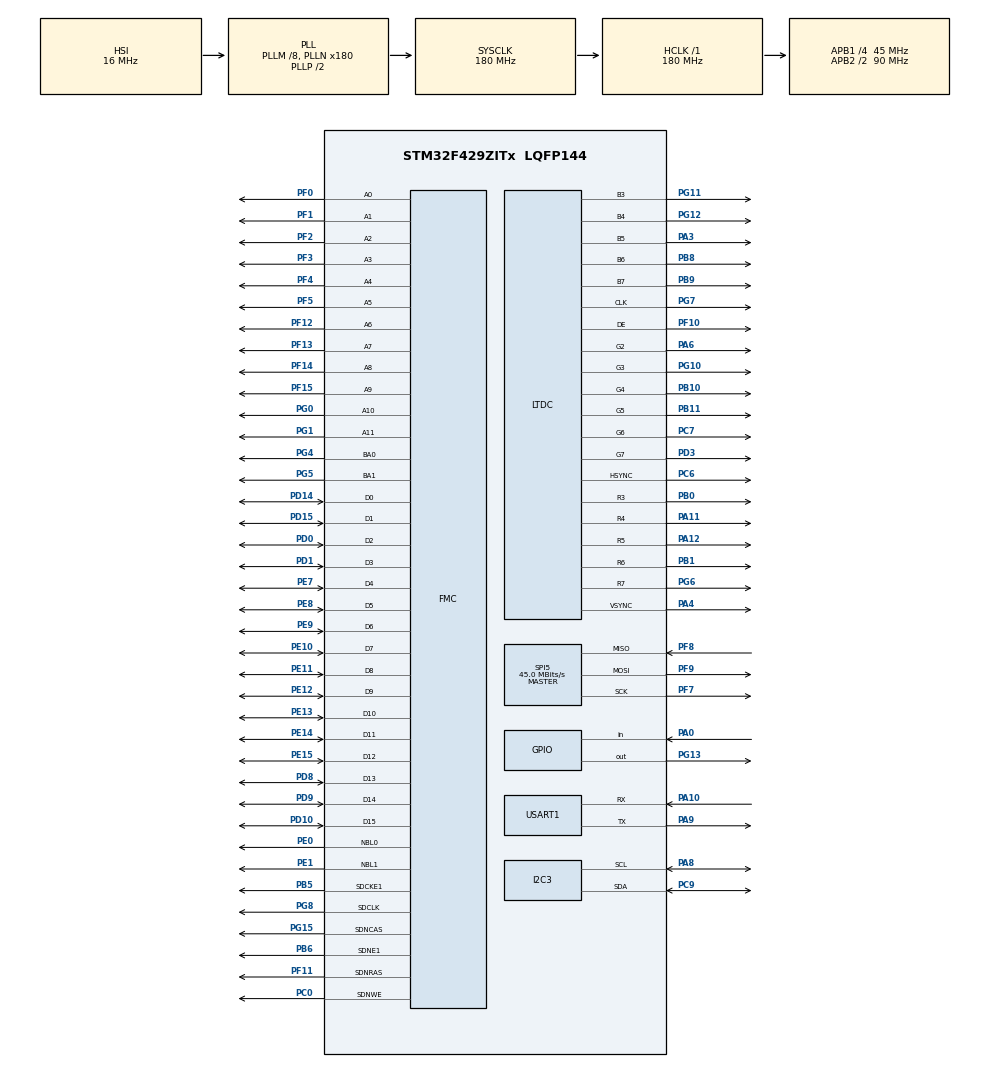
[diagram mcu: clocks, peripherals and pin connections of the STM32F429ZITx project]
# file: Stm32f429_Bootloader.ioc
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Mcu.Family=STM32F4
Mcu.Name=STM32F429ZITx
Mcu.Package=LQFP144
NVIC.PriorityGroup=NVIC_PRIORITYGROUP_4
PA0/WKUP.Signal=GPIO_Input
PA10.Mode=Asynchronous
PA10.Signal=USART1_RX
PA11.Mode=RGB565
PA11.Signal=LTDC_R4
PA12.Mode=RGB565
PA12.Signal=LTDC_R5
PA3.Mode=RGB565
PA3.Signal=LTDC_B5
PA4.Mode=RGB565
PA4.Signal=LTDC_VSYNC
PA6.Mode=RGB565
PA6.Signal=LTDC_G2
PA8.Mode=I2C
PA8.Signal=I2C3_SCL
PA9.Mode=Asynchronous
PA9.Signal=USART1_TX
PB0.Mode=RGB565
PB0.Signal=LTDC_R3
PB1.Mode=RGB565
PB1.Signal=LTDC_R6
PB10.Mode=RGB565
PB10.Signal=LTDC_G4
PB11.Mode=RGB565
PB11.Signal=LTDC_G5
PB5.Mode=SdramChipSelect2_1
PB5.Signal=FMC_SDCKE1
PB6.Mode=SdramChipSelect2_1
PB6.Signal=FMC_SDNE1
PB8.Mode=RGB565
PB8.Signal=LTDC_B6
PB9.Mode=RGB565
PB9.Signal=LTDC_B7
PC0.Signal=FMC_SDNWE
PC6.Mode=RGB565
PC6.Signal=LTDC_HSYNC
PC7.Mode=RGB565
PC7.Signal=LTDC_G6
PC9.Mode=I2C
PC9.Signal=I2C3_SDA
PD0.Signal=FMC_D2_DA2
PD1.Signal=FMC_D3_DA3
PD10.Signal=FMC_D15_DA15
PD14.Signal=FMC_D0_DA0
PD15.Signal=FMC_D1_DA1
PD3.Mode=RGB565
PD3.Signal=LTDC_G7
PD8.Signal=FMC_D13_DA13
PD9.Signal=FMC_D14_DA14
PE0.Signal=FMC_NBL0
PE1.Signal=FMC_NBL1
PE10.Signal=FMC_D7_DA7
PE11.Signal=FMC_D8_DA8
PE12.Signal=FMC_D9_DA9
PE13.Signal=FMC_D10_DA10
PE14.Signal=FMC_D11_DA11
PE15.Signal=FMC_D12_DA12
PE7.Signal=FMC_D4_DA4
PE8.Signal=FMC_D5_DA5
PE9.Signal=FMC_D6_DA6
PF0.Signal=FMC_A0
PF1.Signal=FMC_A1
PF10.Mode=RGB565
PF10.Signal=LTDC_DE
PF11.Signal=FMC_SDNRAS
PF12.Signal=FMC_A6
PF13.Signal=FMC_A7
PF14.Signal=FMC_A8
PF15.Signal=FMC_A9
PF2.Signal=FMC_A2
PF3.Signal=FMC_A3
PF4.Signal=FMC_A4
PF5.Signal=FMC_A5
PF7.Mode=Full_Duplex_Master
PF7.Signal=SPI5_SCK
PF8.Mode=Full_Duplex_Master
PF8.Signal=SPI5_MISO
PF9.Mode=Full_Duplex_Master
PF9.Signal=SPI5_MOSI
PG0.Signal=FMC_A10
PG1.Signal=FMC_A11
PG10.Mode=RGB565
PG10.Signal=LTDC_G3
PG11.Mode=RGB565
PG11.Signal=LTDC_B3
PG12.Mode=RGB565
PG12.Signal=LTDC_B4
PG13.Signal=GPIO_Output
PG15.Signal=FMC_SDNCAS
PG4.Signal=FMC_A14_BA0
PG5.Signal=FMC_A15_BA1
PG6.Mode=RGB565
PG6.Signal=LTDC_R7
PG7.Mode=RGB565
PG7.Signal=LTDC_CLK
PG8.Signal=FMC_SDCLK
ProjectManager.HeapSize=0x200
ProjectManager.StackSize=0x400
ProjectManager.TargetToolchain=STM32CubeIDE
RCC.48MHZClocksFreq_Value=120000000
RCC.AHBFreq_Value=180000000
RCC.APB1CLKDivider=RCC_HCLK_DIV4
RCC.APB1Freq_Value=45000000
RCC.APB1TimFreq_Value=90000000
RCC.APB2CLKDivider=RCC_HCLK_DIV2
RCC.APB2Freq_Value=90000000
RCC.APB2TimFreq_Value=180000000
RCC.CortexFreq_Value=180000000
RCC.HCLKFreq_Value=180000000
RCC.HSE_VALUE=8000000
RCC.HSI_VALUE=16000000
RCC.LSE_VALUE=32768
RCC.PLLM=8
RCC.PLLN=180
RCC.PLLQ=3
RCC.PLLSAIDivR=RCC_PLLSAIDIVR_16
RCC.PLLSAIN=192
RCC.PLLSAIR=4
RCC.SYSCLKFreq_VALUE=180000000
RCC.SYSCLKSource=RCC_SYSCLKSOURCE_PLLCLK
RCC.VCOOutputFreq_Value=360000000
SH.FMC_A0.0=FMC_A0,12b-sda1
SH.FMC_A1.0=FMC_A1,12b-sda1
SH.FMC_A10.0=FMC_A10,12b-sda1
SH.FMC_A11.0=FMC_A11,12b-sda1
SH.FMC_A14_BA0.0=FMC_BA0,FourSdramBanks1
SH.FMC_A15_BA1.0=FMC_BA1,FourSdramBanks1
SH.FMC_A2.0=FMC_A2,12b-sda1
SH.FMC_A3.0=FMC_A3,12b-sda1
SH.FMC_A4.0=FMC_A4,12b-sda1
SH.FMC_A5.0=FMC_A5,12b-sda1
SH.FMC_A6.0=FMC_A6,12b-sda1
SH.FMC_A7.0=FMC_A7,12b-sda1
SH.FMC_A8.0=FMC_A8,12b-sda1
SH.FMC_A9.0=FMC_A9,12b-sda1
SH.FMC_D0_DA0.0=FMC_D0,sd-16b-d1
SH.FMC_D10_DA10.0=FMC_D10,sd-16b-d1
SH.FMC_D11_DA11.0=FMC_D11,sd-16b-d1
SH.FMC_D12_DA12.0=FMC_D12,sd-16b-d1
SH.FMC_D13_DA13.0=FMC_D13,sd-16b-d1
SH.FMC_D14_DA14.0=FMC_D14,sd-16b-d1
SH.FMC_D15_DA15.0=FMC_D15,sd-16b-d1
SH.FMC_D1_DA1.0=FMC_D1,sd-16b-d1
SH.FMC_D2_DA2.0=FMC_D2,sd-16b-d1
SH.FMC_D3_DA3.0=FMC_D3,sd-16b-d1
SH.FMC_D4_DA4.0=FMC_D4,sd-16b-d1
SH.FMC_D5_DA5.0=FMC_D5,sd-16b-d1
SH.FMC_D6_DA6.0=FMC_D6,sd-16b-d1
SH.FMC_D7_DA7.0=FMC_D7,sd-16b-d1
SH.FMC_D8_DA8.0=FMC_D8,sd-16b-d1
SH.FMC_D9_DA9.0=FMC_D9,sd-16b-d1
SH.FMC_NBL0.0=FMC_NBL0,Sd2ByteEnable1
SH.FMC_NBL1.0=FMC_NBL1,Sd2ByteEnable1
SH.FMC_SDCLK.0=FMC_SDCLK,12b-sda1
SH.FMC_SDNCAS.0=FMC_SDNCAS,12b-sda1
SH.FMC_SDNRAS.0=FMC_SDNRAS,12b-sda1
SH.FMC_SDNWE.0=FMC_SDNWE,12b-sda1
SPI5.CalculateBaudRate=45.0 MBits/s
SPI5.Direction=SPI_DIRECTION_2LINES
SPI5.Mode=SPI_MODE_MASTER
SPI5.VirtualType=VM_MASTER
USART1.VirtualMode=VM_ASYNC
VP_CRC_VS_CRC.Mode=CRC_Activate
VP_DMA2D_VS_DMA2D.Mode=DMA2D_Activate
board=STM32F429I-DISC1

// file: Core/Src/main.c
/* USER CODE BEGIN Header */
/**
  ******************************************************************************
  * @file           : main.c
  * @brief          : Main program body
  ******************************************************************************
  * @attention
  *
  * Copyright (c) 2026 STMicroelectronics.
  * All rights reserved.
  *
  * This software is licensed under terms that can be found in the LICENSE file
  * in the root directory of this software component.
  * If no LICENSE file comes with this software, it is provided AS-IS.
  *
  ******************************************************************************
  */
/* USER CODE END Header */
#include "main.h"

/* USER CODE BEGIN Includes */
#include <stdio.h>
#include "STM32F429I-Discovery\stm32f429i_discovery_lcd.h"
/* USER CODE END Includes */

/* USER CODE BEGIN PD */
#define APP_START_ADDRESS   0x08040000
/* USER CODE END PD */

/* USER CODE BEGIN PM */
/* static const uint16_t image_data[10000] = {
    0x0000, 0x0000, 0x0000, 0x0000, 0x0000, 0x0000, 0x0000, 0x0000, 0x0000, 0x0000, 0x0000, 0x0000, 0x0000, 0x0000, 0x0000, 0x0000,
    0x0020, 0x0000, 0x0000, 0x0000, 0x0000, 0x0020, 0x0000, 0x0000, 0x0000, 0x0000, 0x0000, 0x0063, 0x0000, 0x0000, 0x0021, 0x0000,
    0x0000, 0x0000, 0x0000, 0x0041, 0x0129, 0x0062, 0x0021, 0x0000, 0x0000, 0x0021, 0x0000, 0x0000, 0x0021, 0x0042, 0x0000, 0x0000,
    0x0000, 0x0000, 0x0000, 0x0000, 0x0000, 0x0001, 0x0000, 0x0109, 0x0084, 0x0000, 0x00E7, 0x0000, 0x0042, 0x0021, 0x0083, 0x0084,
    0x0084, 0x0041, 0x0000, 0x0000, 0x0000, 0x0000, 0x0000, 0x0000, 0x0000, 0x0021, 0x0021, 0x0000, 0x0021, 0x0042, 0x0000, 0x0000,
    0x0000, 0x0000, 0x0022, 0x0000, 0x0000, 0x0043, 0x0021, 0x0021, 0x0000, 0x0000, 0x0000, 0x0000, 0x0000, 0x0021, 0x0021, 0x0000,
    0x0000, 0x0000, 0x0000, 0x0000, 0x0000, 0x0000, 0x0000, 0x0000, 0x0021, 0x0000, 0x0000, 0x0000, 0x0000, 0x0000, 0x0000, 0x0000,
    0x0000, 0x0000, 0x0000, 0x0000, 0x0021, 0x0000, 0x0000, 0x0000, 0x0000, 0x0063, 0x0000, 0x0000, 0x0000, 0x0000, 0x0021, 0x00A5,
    0x0000, 0x0000, 0x0042, 0x0000, 0x0000, 0x0000, 0x0000, 0x0042, 0x0107, 0x0063, 0x0021, 0x0000, 0x0000, 0x0063, 0x0041, 0x0000,
    0x0021, 0x0021, 0x0000, 0x0000, 0x0000, 0x0000, 0x0000, 0x0000, 0x0000, 0x0042, 0x0021, 0x0109, 0x00A5, 0x0000, 0x00A5, 0x0000,
    0x0063, 0x0021, 0x0083, 0x0062, 0x0063, 0x0042, 0x0000, 0x0000, 0x0000, 0x0000, 0x0000, 0x0000, 0x0000, 0x0021, 0x0042, 0x0000,
    0x0021, 0x0021, 0x0000, 0x0000, 0x0000, 0x0000, 0x0021, 0x0000, 0x0000, 0x0084, 0x0021, 0x0000, 0x0000, 0x0000, 0x0000, 0x0000,
    0x0000, 0x0000, 0x0000, 0x0000, 0x0000, 0x0000, 0x0000, 0x0000, 0x0000, 0x0000, 0x0000, 0x0000, 0x0042, 0x0000, 0x0000, 0x0000,
    0x0000, 0x0000, 0x0000, 0x0000, 0x0000, 0x0000, 0x0000, 0x0000, 0x0021, 0x0000, 0x0000, 0x0000, 0x0000, 0x0084, 0x0000, 0x0000,
    0x0000, 0x0000, 0x0021, 0x0085, 0x0000, 0x0000, 0x0063, 0x0021, 0x0000, 0x0000, 0x0000, 0x0042, 0x0128, 0x0041, 0x0021, 0x0000,
    0x0000, 0x0063, 0x0021, 0x0000, 0x0021, 0x0042, 0x0000, 0x0000, 0x0000, 0x0000, 0x0000, 0x0000, 0x0000, 0x0042, 0x0000, 0x014B,
    0x00A6, 0x0000, 0x018D, 0x0021, 0x0042, 0x0021, 0x0063, 0x0063, 0x0084, 0x0042, 0x0000, 0x0000, 0x0000, 0x0000, 0x0000, 0x0000,
    0x0000, 0x0021, 0x0021, 0x0000, 0x0000, 0x0021, 0x0000, 0x0000, 0x0000, 0x0000, 0x0022, 0x0000, 0x0000, 0x0085, 0x0021, 0x0000,
    0x0000, 0x0000, 0x0000, 0x0000, 0x0000, 0x0021, 0x0021, 0x0000, 0x0000, 0x0000, 0x0000, 0x0000, 0x0000, 0x0000, 0x0000, 0x0000,
    0x0042, 0x0000, 0x0000, 0x0000, 0x0000, 0x0000, 0x0000, 0x0000, 0x0000, 0x0000, 0x0000, 0x0000, 0x0021, 0x0000, 0x0000, 0x0000,
    0x0000, 0x0063, 0x0000, 0x0000, 0x0000, 0x0000, 0x0021, 0x0084, 0x0000, 0x0000, 0x0063, 0x0021, 0x0000, 0x0000, 0x0000, 0x0042,
    0x0129, 0x0063, 0x0042, 0x0000, 0x0000, 0x0042, 0x0021, 0x0000, 0x0021, 0x0042, 0x0000, 0x0000, 0x0000, 0x0000, 0x0000, 0x0000,
    0x0000, 0x0021, 0x0000, 0x014C, 0x00C6, 0x0000, 0x014B, 0x0021, 0x0063, 0x0021, 0x0084, 0x0084, 0x00A4, 0x0042, 0x0000, 0x0000,
    0x0000, 0x0000, 0x0000, 0x0000, 0x0000, 0x0021, 0x0042, 0x0000, 0x0021, 0x0042, 0x0000, 0x0000, 0x0000, 0x0000, 0x0021, 0x0000,
    0x0000, 0x0042, 0x0001, 0x0021, 0x0001, 0x0001, 0x0000, 0x0000, 0x0000, 0x0021, 0x0021, 0x0000, 0x0000, 0x0000, 0x0000, 0x0000,
    0x0000, 0x0000, 0x0000, 0x0000, 0x0021, 0x0000, 0x0000, 0x0000, 0x0000, 0x0000, 0x0000, 0x0000, 0x0000, 0x0000, 0x0000, 0x0000,
    0x0063, 0x0000, 0x0000, 0x0000, 0x0000, 0x0063, 0x0000, 0x0001, 0x0000, 0x0000, 0x0021, 0x0084, 0x0000, 0x0000, 0x0083, 0x0021,
    0x0000, 0x0000, 0x0000, 0x0042, 0x00E6, 0x00A4, 0x0042, 0x0000, 0x0000, 0x0062, 0x0041, 0x0000, 0x0021, 0x0041, 0x0000, 0x0000,
    0x0000, 0x0000, 0x0000, 0x0000, 0x0000, 0x0043, 0x0000, 0x014A, 0x00C6, 0x0000, 0x00C6, 0x0021, 0x0084, 0x0021, 0x0084, 0x0063,
    0x00C5, 0x0063, 0x0000, 0x0000, 0x0000, 0x0000, 0x0000, 0x0000, 0x0000, 0x0042, 0x0063, 0x0000, 0x0042, 0x0084, 0x0000, 0x0000,
    0x0000, 0x0000, 0x0063, 0x0000, 0x0000, 0x0084, 0x0021, 0x0021, 0x0001, 0x0000, 0x0000, 0x0000, 0x0000, 0x0021, 0x0021, 0x0000,
    0x0000, 0x0000, 0x0000, 0x0000, 0x0000, 0x0021, 0x0000, 0x0000, 0x0021, 0x0000, 0x0000, 0x0000, 0x0000, 0x0000, 0x0000, 0x0000,
    0x0000, 0x0000, 0x0000, 0x0000, 0x0063, 0x0000, 0x0000, 0x0000, 0x0000, 0x0084, 0x0021, 0x0021, 0x0000, 0x0000, 0x0021, 0x0042,
    0x0000, 0x0000, 0x0001, 0x0000, 0x0000, 0x0000, 0x0000, 0x0063, 0x0149, 0x0084, 0x0042, 0x0000, 0x0000, 0x00A4, 0x0062, 0x0000,
    0x0021, 0x0042, 0x0000, 0x0000, 0x0000, 0x0000, 0x0000, 0x0000, 0x0000, 0x0021, 0x0000, 0x016B, 0x0108, 0x0000, 0x01CE, 0x0042,
    0x0084, 0x0021, 0x0063, 0x0063, 0x00C5, 0x0063, 0x0000, 0x0000, 0x0000, 0x0000, 0x0000, 0x0000, 0x0000, 0x0021, 0x0021, 0x0000,
    0x0000, 0x0021, 0x0000, 0x0021, 0x0000, 0x0000, 0x0042, 0x0000, 0x0000, 0x00A5, 0x0021, 0x0021, 0x0000, 0x0000, 0x0000, 0x0000,
    0x0000, 0x0042, 0x0021, 0x0000, 0x0000, 0x0000, 0x0000, 0x0000, 0x0000, 0x0000, 0x0000, 0x0000, 0x0020, 0x0000, 0x0000, 0x0000,
    0x0000, 0x0000, 0x0000, 0x0000, 0x0000, 0x0020, 0x0020, 0x0000, 0x0063, 0x0000, 0x0000, 0x0000, 0x0021, 0x0063, 0x0000, 0x0021,
    0x0021, 0x0000, 0x0042, 0x0063, 0x0000, 0x0000, 0x0021, 0x0000, 0x0000, 0x0021, 0x0000, 0x0063, 0x0149, 0x00C5, 0x0063, 0x0000,
    0x0000, 0x0063, 0x0042, 0x0000, 0x0021, 0x0042, 0x0021, 0x0001, 0x0000, 0x0001, 0x0001, 0x0021, 0x0000, 0x0001, 0x0000, 0x00E7,
    0x00A5, 0x0000, 0x01AC, 0x0042, 0x0084, 0x0021, 0x0084, 0x0084, 0x00C5, 0x0063, 0x0000, 0x0000, 0x0000, 0x0000, 0x0000, 0x0000,
    0x0000, 0x0021, 0x0042, 0x0000, 0x0021, 0x0063, 0x0000, 0x0021, 0x0000, 0x0000, 0x0063, 0x0000, 0x0000, 0x0042, 0x0021, 0x0021,
    0x0000, 0x0000, 0x0000, 0x0000, 0x0000, 0x0042, 0x0021, 0x0000, 0x0000, 0x0000, 0x0000, 0x0000, 0x0000, 0x0000, 0x0000, 0x0000,
    0x0021, 0x0000, 0x0000, 0x0000, 0x0000, 0x0000, 0x0000, 0x0000, 0x0000, 0x0000, 0x0000, 0x0000, 0x00A5, 0x0021, 0x0000, 0x0000,
    0x0021, 0x00C5, 0x0000, 0x0021, 0x0001, 0x0000, 0x0042, 0x0084, 0x0000, 0x0000, 0x0042, 0x0021, 0x0000, 0x0021, 0x0000, 0x0062,
    0x0128, 0x00E6, 0x0083, 0x0000, 0x0000, 0x0083, 0x0062, 0x0000, 0x0021, 0x0042, 0x0021, 0x0021, 0x0001, 0x0001, 0x0001, 0x0021,
    0x0063, 0x0043, 0x0000, 0x014A, 0x00E7, 0x0000, 0x00C6, 0x0001, 0x0085, 0x0021, 0x00A5, 0x00A5, 0x00C5, 0x0063, 0x0000, 0x0021,
    0x0021, 0x0021, 0x0021, 0x0021, 0x0000, 0x0063, 0x00A5, 0x0000, 0x0042, 0x0084, 0x0000, 0x0021, 0x0000, 0x0000, 0x00A5, 0x0021,
    0x0000, 0x00A6, 0x0021, 0x0021, 0x0021, 0x0000, 0x0000, 0x0000, 0x0000, 0x0021, 0x0021, 0x0000, 0x0000, 0x0000, 0x0000, 0x0000,
    0x0000, 0x0000, 0x0000, 0x0000, 0x0020, 0x0000, 0x0000, 0x0000, 0x0000, 0x0000, 0x0000, 0x0000, 0x0000, 0x0021, 0x0000, 0x0000,
    0x0084, 0x0021, 0x0000, 0x0001, 0x0021, 0x0084, 0x0000, 0x0021, 0x0021, 0x0000, 0x0042, 0x00C5, 0x0000, 0x0000, 0x0063, 0x0021,
    0x0000, 0x0021, 0x0000, 0x0063, 0x016A, 0x00A4, 0x0062, 0x0000, 0x0000, 0x0063, 0x0062, 0x0000, 0x0042, 0x00C6, 0x0001, 0x0021,
    0x0021, 0x0001, 0x0021, 0x0001, 0x0063, 0x0063, 0x0000, 0x01AD, 0x014A, 0x0000, 0x016B, 0x0021, 0x0085, 0x0042, 0x00A5, 0x0084,
    0x00E6, 0x00A4, 0x0000, 0x0021, 0x0021, 0x0021, 0x0021, 0x0021, 0x0000, 0x0042, 0x0063, 0x0000, 0x0022, 0x00A4, 0x0000, 0x0021,
    0x0000, 0x0000, 0x0042, 0x0000, 0x0000, 0x0085, 0x0022, 0x0042, 0x0021, 0x0000, 0x0000, 0x0000, 0x0000, 0x0042, 0x0042, 0x0000,
    0x0000, 0x0000, 0x0000, 0x0000, 0x0000, 0x0000, 0x0000, 0x0000, 0x0021, 0x0000, 0x0000, 0x0000, 0x0000, 0x0000, 0x0000, 0x0000,
    0x0021, 0x0042, 0x0000, 0x0000, 0x0108, 0x0021, 0x0000, 0x0000, 0x0021, 0x00A4, 0x0000, 0x0062, 0x0042, 0x0000, 0x0042, 0x00A5,
    0x0000, 0x0000, 0x0021, 0x0021, 0x0001, 0x0021, 0x0000, 0x0063, 0x0149, 0x00E6, 0x0063, 0x0000, 0x0000, 0x00A4, 0x0063, 0x0000,
    0x0063, 0x0108, 0x0001, 0x0021, 0x0022, 0x0021, 0x0021, 0x0000, 0x00A5, 0x00C7, 0x0064, 0x0109, 0x00A6, 0x0000, 0x016C, 0x0043,
    0x0085, 0x0043, 0x0107, 0x00C6, 0x00C6, 0x0063, 0x0000, 0x0001, 0x0000, 0x0000, 0x0000, 0x0000, 0x0001, 0x0042, 0x0083, 0x0000,
    0x0042, 0x0084, 0x0021, 0x0021, 0x0000, 0x0000, 0x0084, 0x0021, 0x0000, 0x00C6, 0x0042, 0x0042, 0x0021, 0x0000, 0x0000, 0x0021,
    0x0000, 0x0042, 0x0042, 0x0000, 0x0000, 0x0000, 0x0000, 0x0000, 0x0000, 0x0000, 0x0000, 0x0000, 0x0021, 0x0000, 0x0000, 0x0000,
    0x0000, 0x0000, 0x0000, 0x0000, 0x0042, 0x0021, 0x0000, 0x0021, 0x00A5, 0x0021, 0x0021, 0x0000, 0x0021, 0x00E7, 0x0000, 0x0063,
    0x0042, 0x0000, 0x0042, 0x0063, 0x0000, 0x0021, 0x0042, 0x0021, 0x0001, 0x0022, 0x0021, 0x0063, 0x018B, 0x00A4, 0x0063, 0x0021,
    0x0000, 0x00C5, 0x0084, 0x0000, 0x0043, 0x00A6, 0x0021, 0x0021, 0x0042, 0x0021, 0x0042, 0x0044, 0x00A6, 0x00E8, 0x0043, 0x016B,
    0x00E8, 0x0000, 0x0149, 0x0042, 0x00C7, 0x0085, 0x00E6, 0x0107, 0x00E6, 0x0063, 0x0000, 0x0021, 0x0021, 0x0021, 0x0001, 0x0021,
    0x0021, 0x0063, 0x0107, 0x0000, 0x0063, 0x0107, 0x0021, 0x0021, 0x0001, 0x0000, 0x0149, 0x0063, 0x0000, 0x016B, 0x0063, 0x0042,
    0x0021, 0x0000, 0x0000, 0x0021, 0x0000, 0x0063, 0x0042, 0x0000, 0x0000, 0x0000, 0x0000, 0x0000, 0x0000, 0x0000, 0x0000, 0x0000,
    0x0041, 0x0000, 0x0000, 0x0000, 0x0000, 0x0000, 0x0000, 0x0000, 0x0021, 0x0000, 0x0000, 0x0021, 0x00A4, 0x0021, 0x0021, 0x0021,
    0x0021, 0x00A5, 0x0021, 0x0063, 0x0042, 0x0000, 0x0085, 0x0108, 0x0000, 0x0021, 0x00A5, 0x0042, 0x0021, 0x0042, 0x0021, 0x0084,
    0x01CD, 0x0128, 0x00A4, 0x0021, 0x0021, 0x00A5, 0x0085, 0x0021, 0x0063, 0x00C7, 0x0042, 0x0043, 0x0043, 0x0022, 0x0063, 0x0085,
    0x00E9, 0x010A, 0x0000, 0x016C, 0x014B, 0x0021, 0x02B3, 0x00A6, 0x00C6, 0x00A6, 0x0107, 0x00E6, 0x0128, 0x00C6, 0x0001, 0x0021,
    0x0021, 0x0021, 0x0021, 0x0021, 0x0021, 0x0063, 0x00C6, 0x0000, 0x0084, 0x00E7, 0x0001, 0x0021, 0x0021, 0x0001, 0x00E7, 0x0042,
    0x0000, 0x0063, 0x0021, 0x0063, 0x0021, 0x0000, 0x0000, 0x0020, 0x0000, 0x0042, 0x0042, 0x0000, 0x0000, 0x0000, 0x0000, 0x0000,
    0x0000, 0x0000, 0x0000, 0x0000, 0x0063, 0x0000, 0x0000, 0x0000, 0x0000, 0x0000, 0x0000, 0x0000, 0x0021, 0x0001, 0x0000, 0x0021,
    0x00A4, 0x0021, 0x0021, 0x0000, 0x0021, 0x00A5, 0x0021, 0x0042, 0x0021, 0x0000, 0x0084, 0x0128, 0x0000, 0x0022, 0x0084, 0x0042,
    0x0021, 0x0042, 0x0042, 0x00A5, 0x00E7, 0x00A4, 0x0063, 0x0021, 0x0021, 0x0107, 0x00E7, 0x0021, 0x0084, 0x014A, 0x0064, 0x00A5,
    0x0085, 0x0022, 0x0064, 0x0044, 0x0A30, 0x0A92, 0x0000, 0x01AD, 0x016B, 0x0021, 0x0230, 0x00A5, 0x00C7, 0x00E7, 0x0128, 0x00A5,
    0x00C6, 0x00A5, 0x0001, 0x0021, 0x0022, 0x0042, 0x0021, 0x0021, 0x0021, 0x00A4, 0x0128, 0x0000, 0x00A5, 0x0108, 0x0001, 0x0042,
    0x0021, 0x0021, 0x00C6, 0x0042, 0x0021, 0x00C6, 0x0022, 0x0063, 0x0021, 0x0021, 0x0021, 0x0000, 0x0000, 0x0084, 0x0084, 0x0000,
    0x0000, 0x0000, 0x0000, 0x0000, 0x0000, 0x0000, 0x0000, 0x0000, 0x0042, 0x0000, 0x0000, 0x0000, 0x0000, 0x0000, 0x0000, 0x0000,
    0x0000, 0x0001, 0x0000, 0x0021, 0x0128, 0x0021, 0x0000, 0x0001, 0x0042, 0x00E7, 0x0021, 0x0043, 0x0042, 0x0001, 0x0084, 0x00E7,
    0x0021, 0x0022, 0x00E7, 0x0063, 0x0021, 0x0063, 0x0043, 0x016A, 0x01AB, 0x0128, 0x00C6, 0x0022, 0x0042, 0x0084, 0x00A6, 0x0043,
    0x0084, 0x0109, 0x0064, 0x00A6, 0x00E9, 0x0021, 0x0064, 0x0064, 0x016D, 0x01CE, 0x0001, 0x02D3, 0x0272, 0x0001, 0x01CD, 0x0063,
    0x00E8, 0x0128, 0x0149, 0x00A5, 0x00C5, 0x00A5, 0x0021, 0x0042, 0x0042, 0x0063, 0x0042, 0x0042, 0x0043, 0x0063, 0x00E7, 0x0000,
    0x00C6, 0x018D, 0x0021, 0x0042, 0x0042, 0x0021, 0x00E7, 0x0063, 0x0021, 0x0109, 0x0063, 0x0063, 0x0021, 0x0021, 0x0021, 0x0021,
    0x0000, 0x0042, 0x0041, 0x0000, 0x0000, 0x0000, 0x0000, 0x0000, 0x0000, 0x0000, 0x0000, 0x0000, 0x0042, 0x0000, 0x0000, 0x0000,
    0x0000, 0x0000, 0x0000, 0x0000, 0x0021, 0x0021, 0x0000, 0x0021, 0x00E6, 0x0021, 0x0021, 0x0021, 0x0042, 0x0108, 0x0021, 0x0084,
    0x0042, 0x0000, 0x00A5, 0x0108, 0x0021, 0x0042, 0x00E6, 0x0084, 0x0021, 0x0064, 0x0043, 0x0149, 0x01AB, 0x0128, 0x00E6, 0x0042,
    0x0043, 0x00A6, 0x00A6, 0x0063, 0x0085, 0x00C7, 0x0064, 0x00C7, 0x012B, 0x0021, 0x0063, 0x0043, 0x01EE, 0x01EF, 0x0022, 0x0291,
    0x024F, 0x0064, 0x0398, 0x00E6, 0x0109, 0x0149, 0x01EE, 0x0107, 0x00C6, 0x00A5, 0x0042, 0x0063, 0x0043, 0x00A5, 0x0084, 0x0042,
    0x0063, 0x00A5, 0x0129, 0x0021, 0x00A5, 0x0149, 0x0042, 0x0043, 0x0042, 0x0042, 0x00E7, 0x0063, 0x0042, 0x014A, 0x0063, 0x0085,
    0x0042, 0x0021, 0x0001, 0x0021, 0x0000, 0x0084, 0x0084, 0x0000, 0x0000, 0x0000, 0x0000, 0x0000, 0x0000, 0x0000, 0x0000, 0x0000,
    0x0041, 0x0000, 0x0000, 0x0000, 0x0000, 0x0000, 0x0000, 0x0021, 0x0021, 0x0021, 0x0021, 0x0021, 0x00E7, 0x0021, 0x0021, 0x0021,
    0x0042, 0x00C6, 0x0021, 0x00A4, 0x0063, 0x0043, 0x00E7, 0x01AC, 0x0021, 0x0042, 0x00A5, 0x0063, 0x0022, 0x0085, 0x0064, 0x0128,
    0x020E, 0x0149, 0x00C6, 0x0043, 0x0043, 0x00A6, 0x00C7, 0x0064, 0x00C6, 0x018D, 0x0044, 0x0129, 0x01AE, 0x0043, 0x0085, 0x0064,
    0x020F, 0x0252, 0x0023, 0x0290, 0x01EC, 0x0043, 0x0272, 0x00C6, 0x014B, 0x016A, 0x018B, 0x00E7, 0x0129, 0x0108, 0x0022, 0x00A5,
    0x0064, 0x0022, 0x0042, 0x0043, 0x0043, 0x00C7, 0x01CE, 0x0000, 0x016A, 0x02F5, 0x0022, 0x0084, 0x0043, 0x0084, 0x018D, 0x0085,
    0x0043, 0x01EF, 0x0085, 0x00A6, 0x0043, 0x0021, 0x0021, 0x0021, 0x0000, 0x00A5, 0x00A5, 0x0000, 0x0000, 0x0000, 0x0000, 0x0000,
    0x0000, 0x0000, 0x0000, 0x0021, 0x0042, 0x0000, 0x0021, 0x0000, 0x0000, 0x0000, 0x0000, 0x0000, 0x0021, 0x0021, 0x0021, 0x0022,
    0x0129, 0x0042, 0x0022, 0x0022, 0x0063, 0x00E7, 0x0021, 0x0084, 0x00A6, 0x0042, 0x0107, 0x022F, 0x0022, 0x0063, 0x0084, 0x0063,
    0x0042, 0x00C7, 0x00C6, 0x01AB, 0x02F3, 0x014A, 0x00E7, 0x0063, 0x0063, 0x00C6, 0x00E8, 0x00A6, 0x0085, 0x00E8, 0x0044, 0x016B,
    0x0250, 0x0044, 0x00E8, 0x0084, 0x016D, 0x0211, 0x0024, 0x03D6, 0x0313, 0x0044, 0x0335, 0x00E7, 0x012A, 0x01AB, 0x016B, 0x00E7,
    0x018C, 0x01CE, 0x00E7, 0x0085, 0x00A5, 0x00A5, 0x0064, 0x0064, 0x0064, 0x0063, 0x00C6, 0x0042, 0x0108, 0x0210, 0x0064, 0x0085,
    0x00A6, 0x0109, 0x01EF, 0x00C6, 0x0064, 0x018C, 0x0085, 0x00A5, 0x0063, 0x0021, 0x0021, 0x0021, 0x0000, 0x0021, 0x0001, 0x0000,
    0x0000, 0x0000, 0x0000, 0x0000, 0x0000, 0x0000, 0x0021, 0x0021, 0x0063, 0x0000, 0x0021, 0x0021, 0x0000, 0x0000, 0x0000, 0x0001,
    0x0021, 0x0021, 0x0022, 0x0042, 0x0107, 0x0042, 0x0042, 0x0042, 0x0064, 0x0108, 0x0042, 0x00A5, 0x0064, 0x0022, 0x0108, 0x0270,
    0x0043, 0x0084, 0x0108, 0x00C6, 0x0064, 0x00E7, 0x0108, 0x012A, 0x01AE, 0x01AC, 0x0108, 0x00A7, 0x0085, 0x00E9, 0x00E9, 0x0085,
    0x00A5, 0x016B, 0x0085, 0x0109, 0x020F, 0x0043, 0x00A5, 0x0085, 0x018E, 0x0212, 0x0023, 0x0335, 0x02F3, 0x00A6, 0x041B, 0x0109,
    0x00E8, 0x018C, 0x016C, 0x00E8, 0x0109, 0x0129, 0x00A6, 0x0085, 0x0085, 0x00A5, 0x0085, 0x0084, 0x00A6, 0x012A, 0x0210, 0x0085,
    0x0109, 0x01F1, 0x0064, 0x00C7, 0x014B, 0x00A6, 0x018C, 0x00C6, 0x0084, 0x0210, 0x00C7, 0x00C6, 0x0063, 0x0042, 0x0022, 0x0021,
    0x0000, 0x0063, 0x0063, 0x0000, 0x0000, 0x0000, 0x0000, 0x0000, 0x0000, 0x0000, 0x0000, 0x0021, 0x08A4, 0x0042, 0x0000, 0x0021,
    0x0000, 0x0000, 0x0021, 0x0000, 0x0021, 0x0022, 0x0063, 0x0042, 0x016B, 0x00C5, 0x0064, 0x0084, 0x00A5, 0x0107, 0x0043, 0x00E6,
    0x00A5, 0x0063, 0x00E7, 0x01CE, 0x0084, 0x00A6, 0x00E8, 0x00E7, 0x00A6, 0x0129, 0x0108, 0x01ED, 0x02B2, 0x020F, 0x016A, 0x00C7,
    0x00E7, 0x0149, 0x0108, 0x0084, 0x00A5, 0x0108, 0x0064, 0x0108, 0x018D, 0x0063, 0x0085, 0x00A6, 0x010A, 0x014B, 0x0064, 0x02D3,
    0x02D4, 0x00A7, 0x0231, 0x0109, 0x018F, 0x01F0, 0x01AF, 0x014B, 0x0109, 0x00C7, 0x0064, 0x00A5, 0x0084, 0x00E7, 0x00A5, 0x0084,
    0x00C6, 0x012A, 0x01EF, 0x0085, 0x01AD, 0x0335, 0x00EA, 0x01AF, 0x0109, 0x0085, 0x0210, 0x00E7, 0x00A5, 0x018C, 0x00E7, 0x0108,
    0x0084, 0x0063, 0x0063, 0x0042, 0x0000, 0x0084, 0x00A5, 0x0000, 0x0000, 0x0000, 0x0000, 0x0000, 0x0000, 0x0000, 0x0000, 0x0021,
    0x0042, 0x0083, 0x0021, 0x0000, 0x0000, 0x0021, 0x0021, 0x0021, 0x0021, 0x0042, 0x0063, 0x0086, 0x010B, 0x00A8, 0x0045, 0x0065,
    0x0067, 0x0087, 0x0084, 0x00A7, 0x0087, 0x0087, 0x00A9, 0x016E, 0x0087, 0x00E8, 0x00C8, 0x00CA, 0x00CA, 0x010D, 0x010D, 0x012D,
    0x01AF, 0x018D, 0x00CB, 0x00CB, 0x00CB, 0x014E, 0x00EB, 0x0087, 0x00C8, 0x0089, 0x0086, 0x00E7, 0x014B, 0x0063, 0x00A6, 0x00C7,
    0x00A9, 0x00EB, 0x0089, 0x01D3, 0x01D4, 0x0067, 0x02F4, 0x0129, 0x018E, 0x0191, 0x0192, 0x012C, 0x014B, 0x0109, 0x00A5, 0x0088,
    0x00CB, 0x012D, 0x00A9, 0x00A8, 0x00A9, 0x00C6, 0x0109, 0x0045, 0x00CA, 0x0190, 0x0088, 0x00CA, 0x0065, 0x0086, 0x012E, 0x00C9,
    0x00A8, 0x01D2, 0x00EB, 0x00C9, 0x00E8, 0x00C6, 0x00E7, 0x0063, 0x0021, 0x0021, 0x0021, 0x0000, 0x0000, 0x0000, 0x0000, 0x0000,
    0x0000, 0x0000, 0x0000, 0x0000, 0x0083, 0x0042, 0x0084, 0x0000, 0x0021, 0x0021, 0x0000, 0x0021, 0x0022, 0x0063, 0x0043, 0x198A,
    0x74F7, 0x7D39, 0x64B8, 0x5437, 0x5C99, 0x4374, 0x00A7, 0x3B11, 0x64DA, 0x5499, 0x64BA, 0x64FB, 0x6CD9, 0x098D, 0x11EF, 0x6CFA,
    0x6D3C, 0x7D3C, 0x753B, 0x6CF9, 0x2291, 0x32D1, 0x8539, 0x853A, 0x855B, 0x8D9C, 0x8D9B, 0x959A, 0x3B13, 0x8D7B, 0x42F1, 0x00A8,
    0x010A, 0x0084, 0x00A6, 0x098D, 0x84F8, 0x95DB, 0x8DBB, 0x95BB, 0x95DC, 0x7C98, 0x0358, 0x014A, 0x00A7, 0x4374, 0x9DFD, 0x95BC,
    0x09CE, 0x00A6, 0x098C, 0x9DBB, 0x9DBB, 0x8D7B, 0x855A, 0x751A, 0x5C16, 0x0909, 0x224F, 0x74D8, 0x6CD8, 0x74D8, 0x74F8, 0x6CD9,
    0x5C15, 0x2A90, 0x7DBD, 0x6D1B, 0x64DA, 0x75BD, 0x755B, 0x43B7, 0x012C, 0x00E7, 0x00C7, 0x0042, 0x0001, 0x0084, 0x0063, 0x0000,
    0x0000, 0x0000, 0x0000, 0x0000, 0x0000, 0x0000, 0x0000, 0x0000, 0x0062, 0x0084, 0x0084, 0x0083, 0x0000, 0x0021, 0x0063, 0x0063,
    0x0043, 0x00A5, 0x0045, 0x6391, 0xE7FF, 0x963C, 0x963D, 0x7DDD, 0x8E7F, 0x8E9F, 0x32F2, 0x967F, 0x7E1F, 0x7DDE, 0x8E3E, 0x861E,
    0xB77F, 0x4C17, 0x7D39, 0xB77F, 0x9E9E, 0xB6FF, 0xB6DF, 0xB75F, 0x9E5C, 0x7497, 0xEFBF, 0xDF7F, 0xFFFF, 0xF7DF, 0xE7BF, 0xD75E,
    0x6436, 0xFFFF, 0x4B72, 0x010C, 0x016E, 0x00A5, 0x00CA, 0x7CF9, 0xFFFF, 0xDF7F, 0xCF5F, 0xD77F, 0xE7BF, 0xFFFF, 0x549C, 0x00CA,
    0x09AD, 0xDF7F, 0xFFFF, 0xFFFF, 0x6458, 0x0067, 0x11CD, 0xC6DE, 0xD75F, 0xCF5F, 0xBEFE, 0xB6DF, 0xB79F, 0x5457, 0x32D1, 0xAEDE,
    0x8E3D, 0x967E, 0x8E5E, 0x96DE, 0x7D9B, 0x32F3, 0xA6BE, 0x8E3D, 0x8E3D, 0x963E, 0xB71F, 0xAF7F, 0x1AB4, 0x00C7, 0x0063, 0x0042,
    0x0021, 0x00A5, 0x00A5, 0x0000, 0x0000, 0x0000, 0x0000, 0x0000, 0x0020, 0x0000, 0x0000, 0x0021, 0x0021, 0x0083, 0x0063, 0x00C6,
    0x0021, 0x0000, 0x0063, 0x0042, 0x0042, 0x00C6, 0x0024, 0x6CB6, 0x8E5D, 0x198B, 0x19AC, 0x196A, 0x5435, 0x6DDD, 0x4BB5, 0x6E1F,
    0x19CC, 0x08E8, 0x010A, 0x118C, 0x8E7E, 0x5479, 0x9EBE, 0x6CD8, 0x00CA, 0x096C, 0x00EB, 0x6C76, 0x9EFF, 0x19CD, 0x00EA, 0x2270,
    0xEFDF, 0x7497, 0x092C, 0x00EB, 0x6C34, 0xFFFF, 0x21CB, 0x00A6, 0x014C, 0x0084, 0x00A8, 0xC67C, 0xCEBC, 0x00EA, 0x012A, 0x00E9,
    0x2A90, 0xFFFF, 0x649A, 0x006A, 0x6C56, 0xFFFF, 0x855B, 0xE77F, 0xCEDD, 0x00EA, 0x096A, 0x4BB6, 0x2250, 0x00EA, 0x012A, 0x08E9,
    0x5CB9, 0x761E, 0x21EC, 0x4311, 0x3AD2, 0x3AB1, 0x3A8E, 0x3A8E, 0x19CC, 0x094A, 0x2A50, 0x19EE, 0x220E, 0x2A0F, 0x5C15, 0x973F,
    0x3397, 0x0087, 0x0063, 0x0042, 0x0021, 0x00A5, 0x0084, 0x0000, 0x0000, 0x0000, 0x0000, 0x0000, 0x0020, 0x0021, 0x0000, 0x0021,
    0x0021, 0x0000, 0x0084, 0x0063, 0x00E6, 0x0000, 0x0041, 0x0042, 0x0084, 0x0084, 0x0063, 0x551A, 0x4E1F, 0x5E3F, 0x4DDF, 0x2CDE,
    0x4DFF, 0x32CF, 0x2375, 0x3D1E, 0x00C6, 0x0085, 0x0044, 0x1189, 0x5E1F, 0x4BF5, 0x6E3F, 0x43B4, 0x0046, 0x00A5, 0x00A7, 0x4C35,
    0x765F, 0x0A31, 0x0045, 0x3AEF, 0xE7FF, 0x53D5, 0x0045, 0x0024, 0x9D57, 0xF7DF, 0x00E8, 0x0064, 0x0085, 0x0085, 0x00A7, 0xDF3D,
    0xA5B9, 0x0004, 0x0084, 0x0046, 0x3A8E, 0xFFFF, 0x3B34, 0x094C, 0xBF1E, 0xAEBD, 0x00AB, 0x8518, 0xEFFF, 0x220D, 0x11CD, 0xEFFF,
    0x6C55, 0x0002, 0x0063, 0x0002, 0x5C97, 0x65BD, 0x53D4, 0xAF7F, 0xCFFF, 0xBFFF, 0xBFBF, 0xAFFF, 0x5C55, 0x3B30, 0xA77F, 0x971F,
    0x7E9F, 0x7E3E, 0x7EBF, 0x871F, 0x2B15, 0x00A7, 0x0042, 0x0042, 0x0063, 0x0084, 0x0063, 0x0000, 0x0000, 0x0000, 0x0000, 0x0000,
    0x0000, 0x0042, 0x0000, 0x0000, 0x0041, 0x0000, 0x0084, 0x0000, 0x00E6, 0x0084, 0x0000, 0x0021, 0x0063, 0x0043, 0x08C5, 0x34FD,
    0x33F7, 0x226D, 0x2270, 0x2A4D, 0x347B, 0x22B0, 0x23F8, 0x2C7B, 0x10C6, 0x10E6, 0x08EA, 0x5373, 0x65DF, 0x3B75, 0x3D7F, 0x32F0,
    0x0864, 0x08A3, 0x10C6, 0x75BB, 0x861D, 0x00C8, 0x0002, 0x5BF3, 0xC7FF, 0x2A6F, 0x0023, 0x0064, 0xAE3B, 0xCF5E, 0x196B, 0x114A,
    0x116C, 0x096C, 0x11AD, 0xC77F, 0x8517, 0x0886, 0x1107, 0x0887, 0x6BF4, 0xE7FF, 0x11CD, 0x53F5, 0xAFBF, 0x53F5, 0x7CB6, 0x85DB,
    0xB77F, 0x5C35, 0x21ED, 0xC7BF, 0x5371, 0x1064, 0x1107, 0x10C7, 0x755A, 0x5D3C, 0x3BB4, 0x76FF, 0x5C38, 0x4335, 0x4333, 0x4B75,
    0x21CD, 0x3331, 0x7F1F, 0x5416, 0x4CDA, 0x5E7F, 0x759C, 0x3375, 0x016D, 0x00C6, 0x0063, 0x0042, 0x0021, 0x0129, 0x0128, 0x0000,
    0x0000, 0x0000, 0x0000, 0x0000, 0x0000, 0x0020, 0x0062, 0x0000, 0x0042, 0x0000, 0x0063, 0x0042, 0x0021, 0x0129, 0x0021, 0x0021,
    0x0042, 0x0022, 0x1189, 0x3439, 0x2396, 0x2312, 0x2333, 0x1B13, 0x345A, 0x2B12, 0x2B95, 0x23FA, 0x243C, 0x3CDC, 0x557D, 0x355F,
    0x3CFD, 0x3312, 0x2CBC, 0x2C39, 0x3C99, 0x4498, 0x4D1B, 0x7F1F, 0x6CD8, 0x0002, 0x0001, 0x4C97, 0x875F, 0x19AB, 0x0022, 0x0064,
    0x7DDB, 0x7EDF, 0x8E9E, 0xA6BE, 0x96BE, 0xB73F, 0x857A, 0x8E7E, 0x86DF, 0x965D, 0x9E9D, 0x965C, 0xA73F, 0x96BE, 0x22D3, 0x96FF,
    0x659D, 0x4353, 0x971F, 0x761F, 0x769F, 0x65DD, 0x4394, 0x6EBF, 0x767D, 0x6DFD, 0x75FD, 0x6E1D, 0x66DF, 0x4C79, 0x33F6, 0x673F,
    0x8DFC, 0x655A, 0x6538, 0x5D39, 0x53F4, 0x2B53, 0x4E1F, 0x1129, 0x0088, 0x551C, 0x5DFE, 0x120F, 0x00E9, 0x00E7, 0x0148, 0x00A4,
    0x0021, 0x00C6, 0x00A4, 0x0000, 0x0000, 0x0000, 0x0000, 0x0000, 0x0000, 0x0000, 0x0042, 0x0042, 0x0021, 0x0021, 0x0042, 0x0084,
    0x0000, 0x0084, 0x0129, 0x0000, 0x0042, 0x0021, 0x19EB, 0x4437, 0x33D7, 0x33D7, 0x2B75, 0x2B97, 0x3BF7, 0x08E7, 0x1A6F, 0x345A,
    0x245D, 0x34DF, 0x44FC, 0x34BD, 0x2B34, 0x08A6, 0x3BF7, 0x347D, 0x34FE, 0x34BC, 0x2C7B, 0x44DB, 0x19EC, 0x0022, 0x0022, 0x3C57,
    0x4D1B, 0x08E7, 0x0042, 0x0001, 0x3313, 0x6DFF, 0x6DFE, 0x5DDF, 0x5DBE, 0x6E1D, 0x3B74, 0x3B74, 0x6E1F, 0x6E1F, 0x763F, 0x763F,
    0x7E7F, 0x3B94, 0x3B54, 0x6DFD, 0x2AF1, 0x00C8, 0x096C, 0x092A, 0x4437, 0x453D, 0x5457, 0x453D, 0x4D9D, 0x559E, 0x4D5E, 0x457E,
    0x4D3C, 0x220E, 0x3BB6, 0x5DFE, 0x6DDE, 0x4DFE, 0x55FE, 0x561E, 0x4499, 0x2AD2, 0x5D5D, 0x198A, 0x0044, 0x09AF, 0x551C, 0x5CFB,
    0x08E7, 0x0043, 0x0021, 0x0021, 0x0000, 0x0084, 0x0084, 0x0000, 0x0000, 0x0000, 0x0000, 0x0000, 0x0000, 0x0020, 0x0000, 0x08C5,
    0x0084, 0x0000, 0x0063, 0x0043, 0x0063, 0x0000, 0x014B, 0x00C7, 0x0000, 0x0042, 0x0042, 0x0042, 0x0063, 0x0064, 0x0085, 0x0084,
    0x0063, 0x0042, 0x0022, 0x00C7, 0x0909, 0x090A, 0x00C7, 0x08A7, 0x0044, 0x0001, 0x0065, 0x094B, 0x092A, 0x08C6, 0x08C8, 0x0085,
    0x0022, 0x0064, 0x0043, 0x08C7, 0x09F0, 0x00E9, 0x00E7, 0x01CC, 0x0231, 0x0A74, 0x094C, 0x014C, 0x012B, 0x00E9, 0x00A6, 0x0065,
    0x014C, 0x016D, 0x014C, 0x016E, 0x016D, 0x0065, 0x0109, 0x00C8, 0x0085, 0x0063, 0x00A6, 0x0043, 0x0085, 0x00C8, 0x00A6, 0x08C8,
    0x00C8, 0x00E9, 0x00E9, 0x00E9, 0x0087, 0x0064, 0x00C7, 0x00C8, 0x00EA, 0x00CA, 0x00C9, 0x010B, 0x00A8, 0x00A6, 0x094B, 0x00A6,
    0x00A5, 0x012A, 0x00C8, 0x090A, 0x00C6, 0x0064, 0x0042, 0x0021, 0x0000, 0x098A, 0x096A, 0x0000, 0x0000, 0x0000, 0x0000, 0x0000,
    0x0000, 0x0020, 0x0000, 0x0063, 0x0928, 0x0000, 0x0022, 0x0064, 0x00A5, 0x0063, 0x0001, 0x01CE, 0x00A5, 0x0064, 0x00A5, 0x0085,
    0x012A, 0x00C7, 0x0085, 0x0064, 0x0064, 0x0085, 0x0064, 0x0042, 0x0042, 0x0042, 0x0084, 0x00A6, 0x00C6, 0x00E7, 0x098C, 0x00E8,
    0x0065, 0x0063, 0x0085, 0x0042, 0x0084, 0x00E9, 0x0042, 0x00A6, 0x018C, 0x00C7, 0x00E8, 0x018B, 0x016A, 0x0128, 0x0064, 0x0063,
    0x00A6, 0x0064, 0x0064, 0x0085, 0x0063, 0x0084, 0x0084, 0x0109, 0x00E8, 0x0064, 0x01AF, 0x00C6, 0x0064, 0x0064, 0x0107, 0x0084,
    0x0043, 0x0042, 0x0064, 0x0043, 0x0063, 0x0064, 0x0084, 0x0042, 0x0042, 0x0084, 0x00C6, 0x0084, 0x00A5, 0x0109, 0x00C6, 0x00A6,
    0x00E7, 0x0084, 0x00E8, 0x0084, 0x0042, 0x016C, 0x0063, 0x0021, 0x0085, 0x00C6, 0x0000, 0x0021, 0x0000, 0x00C5, 0x00A5, 0x0000,
    0x0000, 0x0000, 0x0000, 0x0000, 0x0000, 0x0020, 0x0000, 0x0021, 0x00C5, 0x0084, 0x0000, 0x0084, 0x0084, 0x0083, 0x0084, 0x00A5,
    0x0273, 0x020F, 0x0250, 0x0251, 0x03D9, 0x0336, 0x02B2, 0x01AE, 0x014D, 0x014C, 0x00C7, 0x0084, 0x0064, 0x0086, 0x00C8, 0x0108,
    0x01CC, 0x024F, 0x2399, 0x09EF, 0x00CA, 0x0085, 0x00A6, 0x0063, 0x0042, 0x00C6, 0x0042, 0x0108, 0x00A6, 0x0043, 0x0084, 0x0044,
    0x0064, 0x0064, 0x0085, 0x0085, 0x00C7, 0x00C6, 0x00E8, 0x012B, 0x00E8, 0x00E8, 0x00C7, 0x01F1, 0x01AF, 0x0084, 0x02B4, 0x012A,
    0x00A7, 0x0064, 0x0128, 0x0085, 0x0085, 0x00E8, 0x00A6, 0x0085, 0x0085, 0x0064, 0x0064, 0x00C7, 0x0042, 0x0084, 0x0109, 0x0085,
    0x00A6, 0x012A, 0x0148, 0x0148, 0x01AA, 0x0106, 0x0149, 0x0084, 0x0042, 0x01AD, 0x0063, 0x0064, 0x0042, 0x0021, 0x0000, 0x0021,
    0x0000, 0x08A4, 0x0884, 0x0000, 0x0000, 0x0000, 0x0000, 0x0000, 0x0000, 0x0000, 0x0000, 0x0083, 0x0042, 0x00A5, 0x0042, 0x0000,
    0x00E7, 0x0063, 0x0042, 0x0000, 0x0063, 0x00A5, 0x00A5, 0x00E6, 0x014A, 0x0129, 0x0129, 0x0085, 0x0084, 0x0042, 0x0021, 0x0021,
    0x0021, 0x0042, 0x016B, 0x0021, 0x0001, 0x0022, 0x0043, 0x0043, 0x0042, 0x0022, 0x00E7, 0x0084, 0x0022, 0x0042, 0x0043, 0x0043,
    0x0064, 0x00E8, 0x00A5, 0x00E7, 0x00E8, 0x00C7, 0x00C7, 0x00C8, 0x00E9, 0x0109, 0x012A, 0x016D, 0x012B, 0x016C, 0x016C, 0x0253,
    0x01CF, 0x00E8, 0x0336, 0x018D, 0x00A6, 0x00C7, 0x016B, 0x00C7, 0x00A6, 0x012B, 0x00C7, 0x00E8, 0x00E8, 0x00C7, 0x0084, 0x00A5,
    0x0042, 0x0063, 0x0108, 0x0084, 0x0084, 0x018B, 0x0042, 0x0064, 0x0086, 0x0021, 0x00C7, 0x0064, 0x0063, 0x02B1, 0x0084, 0x0064,
    0x0063, 0x0063, 0x0021, 0x0042, 0x0021, 0x1148, 0x1149, 0x0000, 0x0021, 0x0000, 0x0000, 0x0000, 0x0000, 0x0021, 0x0000, 0x0042,
    0x0042, 0x0020, 0x00E7, 0x0000, 0x0042, 0x0129, 0x0042, 0x0000, 0x0001, 0x0043, 0x0064, 0x0044, 0x016B, 0x012B, 0x012C, 0x00A6,
    0x0085, 0x0064, 0x0064, 0x0064, 0x0064, 0x00A5, 0x022E, 0x0022, 0x0043, 0x0021, 0x0063, 0x0085, 0x0063, 0x0022, 0x0129, 0x0084,
    0x0043, 0x00A6, 0x0063, 0x0064, 0x00A6, 0x00A5, 0x00E7, 0x0129, 0x00C6, 0x00E8, 0x00E8, 0x0109, 0x012B, 0x0232, 0x0210, 0x016C,
    0x01F1, 0x0A12, 0x09F1, 0x02B5, 0x0254, 0x01AF, 0x049D, 0x0231, 0x016C, 0x014B, 0x01CE, 0x012A, 0x012A, 0x012A, 0x014C, 0x016C,
    0x016C, 0x012A, 0x00E8, 0x0084, 0x0084, 0x00E7, 0x0149, 0x0064, 0x0084, 0x01AB, 0x0064, 0x0085, 0x0085, 0x0021, 0x014A, 0x00A5,
    0x0063, 0x0374, 0x00A4, 0x0063, 0x0084, 0x0084, 0x0021, 0x0021, 0x0021, 0x08E6, 0x0906, 0x0000, 0x0020, 0x0000, 0x0000, 0x0000,
    0x0000, 0x0021, 0x0000, 0x0042, 0x0083, 0x0000, 0x0083, 0x08E6, 0x0000, 0x0084, 0x0129, 0x00C6, 0x0062, 0x0083, 0x0084, 0x0062,
    0x016A, 0x0128, 0x00A6, 0x0063, 0x0042, 0x0021, 0x0021, 0x0021, 0x0021, 0x0042, 0x016A, 0x0021, 0x0042, 0x0084, 0x0064, 0x0085,
    0x0042, 0x0022, 0x00E8, 0x0084, 0x00A6, 0x0085, 0x0063, 0x0084, 0x00E8, 0x0109, 0x014E, 0x0171, 0x0192, 0x01D3, 0x01F3, 0x0233,
    0x02B5, 0x02F8, 0x037B, 0x03DC, 0x043E, 0x14FF, 0x14DF, 0x04FF, 0x049F, 0x035C, 0x05DF, 0x031A, 0x0257, 0x01F4, 0x01F5, 0x0192,
    0x01B2, 0x01D2, 0x0190, 0x01B1, 0x01D2, 0x016F, 0x016F, 0x014D, 0x00A6, 0x00A5, 0x0108, 0x0064, 0x00A5, 0x028F, 0x0063, 0x0085,
    0x0063, 0x0001, 0x0129, 0x0084, 0x0022, 0x016A, 0x0043, 0x0043, 0x0063, 0x0063, 0x0000, 0x0021, 0x0000, 0x08A4, 0x00A4, 0x0000,
    0x0020, 0x0000, 0x0000, 0x0000, 0x0000, 0x0062, 0x0000, 0x00A4, 0x0083, 0x0021, 0x0000, 0x0108, 0x0063, 0x0000, 0x0000, 0x00C5,
    0x00A4, 0x0084, 0x00A4, 0x0084, 0x01AB, 0x00E7, 0x00E7, 0x0042, 0x0064, 0x0021, 0x0021, 0x0021, 0x0021, 0x0063, 0x01CC, 0x0021,
    0x0042, 0x0064, 0x0084, 0x0085, 0x00E7, 0x0042, 0x014B, 0x0085, 0x00A5, 0x0085, 0x0084, 0x00C6, 0x00EC, 0x1296, 0x5CDD, 0x6D9F,
    0x761F, 0x765F, 0x75FF, 0x75BF, 0x6DBF, 0x6D9F, 0x6DFF, 0x765F, 0x86BF, 0x8F5F, 0x8F5F, 0x8F7F, 0x8F3F, 0x86BF, 0x9F9F, 0x7EBF,
    0x765F, 0x763F, 0x761F, 0x75DE, 0x6DBE, 0x75DE, 0x6DBE, 0x6DBE, 0x6DFF, 0x6D9E, 0x655C, 0x6DFE, 0x0AF5, 0x00E9, 0x01CD, 0x0085,
    0x00C6, 0x0290, 0x0084, 0x00A6, 0x0063, 0x0000, 0x018B, 0x00A5, 0x0022, 0x02D2, 0x0063, 0x0042, 0x0063, 0x0084, 0x0021, 0x0041,
    0x0000, 0x0927, 0x116A, 0x0000, 0x0000, 0x0000, 0x0000, 0x0000, 0x0021, 0x0063, 0x0021, 0x00A4, 0x00A4, 0x0042, 0x0020, 0x0021,
    0x016A, 0x0128, 0x0149, 0x01AB, 0x0108, 0x00E7, 0x00C7, 0x00C6, 0x016A, 0x00E8, 0x0042, 0x0021, 0x0021, 0x0042, 0x0021, 0x0021,
    0x0021, 0x0063, 0x01EC, 0x0022, 0x0042, 0x0043, 0x0085, 0x0084, 0x014A, 0x0063, 0x00C7, 0x0063, 0x00A6, 0x00A6, 0x00A6, 0x00CA,
    0x43D9, 0x9F1F, 0x661E, 0x3D7E, 0x357E, 0x359E, 0x3D9E, 0x357E, 0x357E, 0x35BF, 0x3DFF, 0x469F, 0x5EDF, 0x773F, 0x877F, 0x8F9F,
    0x8F9F, 0x777F, 0x5F1F, 0x46BF, 0x3E7F, 0x361F, 0x359F, 0x357E, 0x353D, 0x2D1D, 0x2D1D, 0x2D1D, 0x2D1C, 0x2CFD, 0x4DBE, 0xBEDE,
    0x016D, 0x00E7, 0x022E, 0x00A6, 0x00E7, 0x098B, 0x0084, 0x00C7, 0x0084, 0x0021, 0x0107, 0x0084, 0x0042, 0x01EE, 0x0063, 0x0042,
    0x0063, 0x0084, 0x0000, 0x0021, 0x0000, 0x08A5, 0x08E6, 0x0000, 0x0000, 0x0000, 0x0000, 0x0000, 0x0000, 0x0021, 0x0000, 0x0062,
    0x0063, 0x0021, 0x0042, 0x0000, 0x0042, 0x0083, 0x0083, 0x00A4, 0x0062, 0x0063, 0x0128, 0x0043, 0x0128, 0x0042, 0x0043, 0x0042,
    0x0021, 0x0022, 0x0021, 0x0042, 0x0021, 0x0084, 0x02F0, 0x0021, 0x0042, 0x0042, 0x00A7, 0x0084, 0x016A, 0x0084, 0x01AE, 0x00A6,
    0x00C7, 0x00C7, 0x0087, 0x3B56, 0x8E9F, 0x0B16, 0x0213, 0x0295, 0x02D7, 0x02D8, 0x02D7, 0x02D8, 0x02F8, 0x033A, 0x03FD, 0x04DF,
    0x159F, 0x365F, 0x571F, 0x675F, 0x673F, 0x4EFF, 0x369F, 0x15BF, 0x04DF, 0x03DE, 0x033C, 0x031A, 0x02B7, 0x0275, 0x0275, 0x0275,
    0x0294, 0x0235, 0x6D5D, 0x53D5, 0x0025, 0x00A5, 0x018B, 0x0084, 0x00C6, 0x0353, 0x00A6, 0x00E8, 0x0064, 0x0021, 0x014A, 0x0084,
    0x0022, 0x0270, 0x0084, 0x0042, 0x0084, 0x00C6, 0x0000, 0x0021, 0x0000, 0x00C5, 0x08E6, 0x0000, 0x0000, 0x0000, 0x0000, 0x0000,
    0x0000, 0x0021, 0x0000, 0x0063, 0x0062, 0x0000, 0x0021, 0x0063, 0x0000, 0x0000, 0x0000, 0x0000, 0x0000, 0x0042, 0x016A, 0x0000,
    0x0128, 0x0063, 0x0001, 0x0021, 0x0021, 0x0042, 0x0021, 0x0063, 0x0021, 0x0042, 0x0148, 0x0042, 0x0084, 0x0021, 0x00C7, 0x00A6,
    0x018A, 0x00A5, 0x014B, 0x00A5, 0x0109, 0x00C7, 0x096D, 0x861F, 0x0A92, 0x01AD, 0x0A50, 0x0274, 0x0359, 0x0C3B, 0x147B, 0x149C,
    0x14DD, 0x14FD, 0x1D9E, 0x363F, 0x5EFF, 0x877F, 0xAFBF, 0xAFDF, 0xAFBF, 0x9FBF, 0x7F7F, 0x56FF, 0x369F, 0x1DBF, 0x151E, 0x14FE,
    0x1D1D, 0x1CFC, 0x147C, 0x145B, 0x0C1A, 0x249C, 0xAE9F, 0x098D, 0x00A6, 0x012A, 0x022E, 0x00A6, 0x0128, 0x1374, 0x00A6, 0x00E8,
    0x0085, 0x0021, 0x0149, 0x0084, 0x0021, 0x0314, 0x00C6, 0x0042, 0x0084, 0x00C6, 0x0021, 0x0021, 0x0000, 0x118A, 0x11CD, 0x0000,
    0x0020, 0x0000, 0x0000, 0x0000, 0x0000, 0x0021, 0x0000, 0x0063, 0x0084, 0x0000, 0x0000, 0x0063, 0x0042, 0x0084, 0x0084, 0x0042,
    0x0042, 0x0021, 0x0107, 0x0000, 0x028F, 0x00E6, 0x0000, 0x0042, 0x0084, 0x0021, 0x0021, 0x0064, 0x0021, 0x0063, 0x024E, 0x0042,
    0x00C5, 0x0021, 0x00E8, 0x00A7, 0x01AA, 0x00A5, 0x018C, 0x00C6, 0x018C, 0x010C, 0x43F9, 0x4C99, 0x010A, 0x0A0E, 0x0273, 0x4D1C,
    0xB75F, 0xE7FF, 0xE7FF, 0xEFFF, 0xE7FF, 0xE7FF, 0xEFFF, 0xEFFF, 0xFFFF, 0xFFFF, 0xFFFF, 0xFFFF, 0xFFFF, 0xFFFF, 0xFFFF, 0xF7FF,
    0xEFFF, 0xE7FF, 0xDFFF, 0xDFFF, 0xDFFF, 0xDFFF, 0xD7FF, 0xD7FF, 0xCFDF, 0xEFFF, 0x5BF5, 0x0087, 0x0109, 0x012A, 0x020E, 0x00C7,
    0x0149, 0x01CD, 0x0084, 0x0109, 0x0085, 0x0000, 0x016A, 0x0084, 0x0021, 0x024F, 0x00A5, 0x0042, 0x0084, 0x00A5, 0x0000, 0x0021,
    0x0000, 0x00A4, 0x08C5, 0x0000, 0x0000, 0x0000, 0x0000, 0x0000, 0x0000, 0x0021, 0x0000, 0x0083, 0x08A5, 0x0021, 0x0000, 0x0021,
    0x0062, 0x0084, 0x00A5, 0x0063, 0x0000, 0x0021, 0x0107, 0x0000, 0x00C6, 0x0063, 0x0021, 0x0021, 0x0021, 0x0021, 0x0021, 0x0063,
    0x0021, 0x0063, 0x01CC, 0x0042, 0x0107, 0x0063, 0x012A, 0x00C7, 0x024E, 0x00E7, 0x01AD, 0x0108, 0x012A, 0x016F, 0x6D9F, 0x12B2,
    0x018B, 0x0253, 0x7E1E, 0xFFFF, 0xF79F, 0x6C15, 0x4312, 0x4AF0, 0x42CF, 0x42AF, 0x42CF, 0x42D0, 0x3AF2, 0x3B55, 0x3B76, 0x3B96,
    0x3B75, 0x3B55, 0x3B34, 0x3AF2, 0x3AB0, 0x3AAF, 0x3A8F, 0x3A8F, 0x3A8F, 0x326D, 0x3A6D, 0x3A6D, 0x3A6D, 0x3A8E, 0x00E7, 0x00A5,
    0x010B, 0x018E, 0x01AC, 0x00C7, 0x0129, 0x0312, 0x0085, 0x010A, 0x00C7, 0x0000, 0x018A, 0x0084, 0x0021, 0x03F6, 0x0107, 0x0022,
    0x0085, 0x00A5, 0x0000, 0x0021, 0x0000, 0x0084, 0x0084, 0x0000, 0x0000, 0x0000, 0x0000, 0x0000, 0x0000, 0x0021, 0x0000, 0x0042,
    0x0020, 0x0020, 0x0041, 0x0042, 0x0042, 0x0042, 0x0042, 0x0084, 0x0042, 0x0042, 0x01CC, 0x0000, 0x00E6, 0x0062, 0x0021, 0x0000,
    0x0063, 0x00A5, 0x0021, 0x0084, 0x0021, 0x0063, 0x02F0, 0x0063, 0x0128, 0x00A6, 0x014C, 0x0109, 0x0129, 0x00A6, 0x018C, 0x0109,
    0x010A, 0x1AD5, 0x657D, 0x018D, 0x01AF, 0x54FC, 0xFFFF, 0xE77E, 0x222F, 0x0025, 0x0065, 0x0045, 0x0065, 0x0065, 0x0065, 0x0086,
    0x0087, 0x00C8, 0x00C8, 0x00C8, 0x00C8, 0x00C8, 0x00C8, 0x00A7, 0x0065, 0x0045, 0x0045, 0x0065, 0x0065, 0x0086, 0x0043, 0x0043,
    0x0023, 0x0044, 0x00A6, 0x0085, 0x00A7, 0x012A, 0x01CC, 0x0108, 0x016B, 0x02D1, 0x00A5, 0x012B, 0x00E9, 0x0000, 0x016A, 0x00A4,
    0x0021, 0x02B0, 0x00C5, 0x0042, 0x00C6, 0x00C6, 0x0021, 0x0021, 0x0000, 0x00C6, 0x0907, 0x0000, 0x0021, 0x0000, 0x0000, 0x0000,
    0x0000, 0x0021, 0x0000, 0x0084, 0x0021, 0x0000, 0x0000, 0x0021, 0x0021, 0x0020, 0x0021, 0x0084, 0x0042, 0x0063, 0x020C, 0x0000,
    0x01CB, 0x0084, 0x0001, 0x0000, 0x0084, 0x00A5, 0x0021, 0x00A5, 0x0021, 0x0042, 0x026F, 0x0063, 0x0169, 0x0063, 0x00E8, 0x012B,
    0x02B1, 0x0108, 0x0230, 0x012A, 0x014D, 0x4CDD, 0x3C17, 0x010A, 0x0AB4, 0xDF7F, 0xFFFF, 0x63D3, 0x0004, 0x00A5, 0x0085, 0x00A6,
    0x00C6, 0x00E8, 0x0109, 0x012A, 0x016D, 0x018E, 0x01B0, 0x01AF, 0x01B0, 0x01B0, 0x01D0, 0x014C, 0x00E8, 0x00E8, 0x0108, 0x00C7,
    0x00C7, 0x00E8, 0x00C7, 0x00C7, 0x00A6, 0x00A5, 0x00A6, 0x00A5, 0x0085, 0x016B, 0x020F, 0x0063, 0x0108, 0x1333, 0x00A5, 0x014B,
    0x00C7, 0x0000, 0x0128, 0x0084, 0x0021, 0x01CB, 0x0084, 0x0042, 0x0084, 0x00C6, 0x0021, 0x0021, 0x0000, 0x0063, 0x0063, 0x0000,
    0x0000, 0x0000, 0x0000, 0x0000, 0x0000, 0x0000, 0x0000, 0x0041, 0x0020, 0x0042, 0x0000, 0x0021, 0x0000, 0x0000, 0x0000, 0x0021,
    0x0042, 0x0042, 0x00A4, 0x0000, 0x01AA, 0x00A4, 0x0021, 0x0042, 0x0042, 0x0043, 0x0021, 0x00C7, 0x0021, 0x00A4, 0x02F2, 0x0084,
    0x0127, 0x0043, 0x016B, 0x0292, 0x01EF, 0x012B, 0x0251, 0x016B, 0x01F3, 0x6DDF, 0x1250, 0x010A, 0x43F8, 0xFFFF, 0xF79E, 0x198A,
    0x0065, 0x00A6, 0x116A, 0x118C, 0x11EF, 0x1231, 0x1294, 0x12D6, 0x1359, 0x139B, 0x13FD, 0x143D, 0x143D, 0x13FD, 0x13BD, 0x12D8,
    0x016C, 0x0109, 0x012B, 0x09F0, 0x1272, 0x1252, 0x1252, 0x1252, 0x1210, 0x014A, 0x00E8, 0x00C7, 0x0085, 0x00C7, 0x01AD, 0x0043,
    0x0108, 0x0C77, 0x00C6, 0x016B, 0x0085, 0x0000, 0x01ED, 0x0107, 0x0021, 0x03B5, 0x0106, 0x0022, 0x00C6, 0x00E6, 0x0000, 0x0021,
    0x0000, 0x00A5, 0x08E6, 0x0000, 0x0000, 0x0000, 0x0000, 0x0000, 0x0000, 0x0000, 0x0000, 0x0083, 0x0021, 0x0041, 0x0000, 0x0000,
    0x0000, 0x0000, 0x0000, 0x0021, 0x0020, 0x0062, 0x01EC, 0x0021, 0x00C6, 0x0083, 0x0042, 0x0064, 0x0063, 0x0063, 0x0021, 0x00E8,
    0x0021, 0x00E6, 0x04B9, 0x00C5, 0x01AA, 0x0022, 0x0A2F, 0x1BFA, 0x02F4, 0x01CD, 0x0AB3, 0x01F1, 0x23DB, 0x655C, 0x012B, 0x012B,
    0x6CFA, 0xFFFF, 0xD71D, 0x094A, 0x0085, 0x0086, 0x7D1A, 0x8E5F, 0x863F, 0x8E7F, 0x9EDF, 0xAF1F, 0xBF5F, 0xBF5F, 0xBF7F, 0xB75F,
    0xB77F, 0xBF5F, 0xCF9F, 0xBF3F, 0x11CE, 0x00C9, 0x1A30, 0xC71F, 0xAEFF, 0x9EBF, 0x8E7F, 0x865F, 0x8EBF, 0x32D1, 0x010B, 0x00E8,
    0x0085, 0x00A6, 0x01AD, 0x0063, 0x0169, 0x1B35, 0x00E7, 0x01CD, 0x00A6, 0x0000, 0x00C6, 0x0084, 0x0021, 0x01CB, 0x0084, 0x0043,
    0x00C5, 0x00C6, 0x0000, 0x0062, 0x0041, 0x0108, 0x098B, 0x0000, 0x0000, 0x0000, 0x0000, 0x0000, 0x0000, 0x0000, 0x0000, 0x0084,
    0x0021, 0x0041, 0x0000, 0x0000, 0x0000, 0x0000, 0x0000, 0x0021, 0x0021, 0x0063, 0x024E, 0x0021, 0x022E, 0x00E6, 0x0000, 0x0000,
    0x0021, 0x0042, 0x0020, 0x00E8, 0x0021, 0x0084, 0x024E, 0x0085, 0x01EB, 0x0043, 0x012A, 0x01AF, 0x020F, 0x016C, 0x0231, 0x01D2,
    0x559F, 0x33B5, 0x00E9, 0x010A, 0x751A, 0xE7DF, 0xDF7F, 0x11AC, 0x0085, 0x0065, 0x21ED, 0xC73F, 0xB71F, 0xBF3F, 0xCF5F, 0xDF9F,
    0xE7BF, 0xEFBF, 0xEFBF, 0xE79F, 0xE79F, 0xEFBF, 0xFFFF, 0xA5FB, 0x00C9, 0x00A8, 0x6415, 0xDFDF, 0x967F, 0x7E3F, 0x6DDF, 0x5DBF,
    0x6E1F, 0x116A, 0x012C, 0x00E8, 0x0085, 0x014B, 0x01AD, 0x0064, 0x024E, 0x1D1B, 0x0107, 0x020E, 0x00E9, 0x0000, 0x00C5, 0x0107,
    0x0000, 0x014A, 0x0064, 0x0042, 0x00A5, 0x00C6, 0x0000, 0x0021, 0x0000, 0x00C6, 0x0949, 0x0000, 0x0000, 0x0000, 0x0000, 0x0000,
    0x0000, 0x0000, 0x0000, 0x0084, 0x0021, 0x0021, 0x0000, 0x0000, 0x0000, 0x0000, 0x0021, 0x0021, 0x0021, 0x0041, 0x0127, 0x0021,
    0x024E, 0x00E5, 0x0020, 0x0063, 0x0042, 0x0042, 0x0020, 0x00E8, 0x0021, 0x00C5, 0x0B94, 0x00A5, 0x01EA, 0x0022, 0x0129, 0x0250,
    0x0336, 0x01AD, 0x01AF, 0x0277, 0x6DFF, 0x01CE, 0x0108, 0x00C8, 0x6498, 0xCF7F, 0xE7DF, 0x5BF5, 0x0067, 0x0907, 0x0024, 0x5BB3,
    0xCF9F, 0xAEDF, 0xC73F, 0xD77F, 0xDF9F, 0xE7BF, 0xEFBF, 0xEFBF, 0xEFDF, 0xF7BF, 0xFFFF, 0x4B72, 0x0086, 0x00E9, 0xA61B, 0xA6FF,
    0x6DDF, 0x5D7F, 0x551E, 0x559F, 0x5CFA, 0x0045, 0x01AE, 0x00E8, 0x00A6, 0x0109, 0x01EE, 0x0085, 0x01AB, 0x1313, 0x00A5, 0x016D,
    0x00C8, 0x0000, 0x01CB, 0x026F, 0x0000, 0x0335, 0x00C5, 0x0021, 0x0084, 0x00A4, 0x0000, 0x0021, 0x0000, 0x08E6, 0x0928, 0x0000,
    0x0000, 0x0000, 0x0000, 0x0000, 0x0000, 0x0000, 0x0000, 0x0063, 0x0021, 0x0041, 0x0000, 0x0000, 0x0000, 0x0000, 0x0000, 0x0020,
    0x0021, 0x0021, 0x01EC, 0x0042, 0x00E5, 0x0063, 0x0041, 0x0084, 0x0084, 0x0021, 0x0021, 0x0109, 0x0001, 0x00E6, 0x053A, 0x00C5,
    0x01CA, 0x0042, 0x0129, 0x01F0, 0x02B3, 0x01EF, 0x0275, 0x2CDE, 0x5D1A, 0x00EA, 0x0129, 0x00C7, 0x3313, 0xB73F, 0xB6FF, 0xC71E,
    0x11AE, 0x00C7, 0x00A5, 0x0065, 0x857B, 0x96BF, 0x863F, 0x9EBF, 0xAEDF, 0xBF1F, 0xC75F, 0xC73F, 0xCF5F, 0xDF9F, 0xD75F, 0x116A,
    0x0086, 0x222E, 0xAEDF, 0x5D9F, 0x44DE, 0x3C9C, 0x343B, 0x4D9F, 0x3B95, 0x0024, 0x0252, 0x0129, 0x00A7, 0x0129, 0x0272, 0x00E9,
    0x018A, 0x12D2, 0x00A5, 0x01AD, 0x00C8, 0x0000, 0x00C6, 0x0107, 0x0021, 0x0251, 0x0084, 0x0000, 0x0084, 0x00C5, 0x0000, 0x0021,
    0x0000, 0x0062, 0x0083, 0x0000, 0x0000, 0x0000, 0x0000, 0x0000, 0x0000, 0x0000, 0x0000, 0x00A4, 0x0021, 0x0041, 0x0000, 0x0000,
    0x0000, 0x0021, 0x0000, 0x0000, 0x0021, 0x0021, 0x026E, 0x0000, 0x02B2, 0x00C5, 0x0000, 0x0063, 0x0084, 0x0021, 0x0021, 0x0109,
    0x0021, 0x00A4, 0x0373, 0x00A5, 0x01CA, 0x0042, 0x00C7, 0x014B, 0x02B2, 0x0232, 0x035A, 0x669F, 0x2B33, 0x00C8, 0x0108, 0x00E7,
    0x014B, 0x85FD, 0x865F, 0xB71F, 0x8DBB, 0x00CA, 0x00E7, 0x0064, 0x1969, 0x8E3E, 0x5DBF, 0x6DDF, 0x7E3F, 0x8E7F, 0x9EBF, 0xA6BF,
    0xA6BF, 0xCF9F, 0x9D79, 0x0065, 0x00A7, 0x5C15, 0x763F, 0x345C, 0x33F9, 0x2BD8, 0x23D9, 0x5DBE, 0x11AC, 0x0085, 0x014D, 0x00E8,
    0x00C7, 0x012A, 0x0251, 0x0084, 0x01AA, 0x1353, 0x00A5, 0x018D, 0x00C7, 0x0000, 0x0107, 0x016A, 0x0001, 0x0376, 0x0063, 0x00E7,
    0x0128, 0x00E7, 0x0000, 0x0042, 0x0000, 0x00E6, 0x014A, 0x0000, 0x0020, 0x0000, 0x0000, 0x0000, 0x0000, 0x0000, 0x0000, 0x0083,
    0x0021, 0x0042, 0x0021, 0x0000, 0x0000, 0x0020, 0x0000, 0x0021, 0x0021, 0x0042, 0x01CA, 0x0021, 0x026F, 0x00C5, 0x0000, 0x0021,
    0x0042, 0x0042, 0x0021, 0x0129, 0x0042, 0x00A4, 0x0291, 0x00A5, 0x0A0C, 0x0042, 0x00A5, 0x0109, 0x0376, 0x02B8, 0x0CBD, 0x767F,
    0x016C, 0x00C7, 0x00C7, 0x00E7, 0x00C7, 0x2292, 0x7E5F, 0x65BF, 0xAF3F, 0x5C57, 0x0067, 0x00E6, 0x0003, 0x42F0, 0x763F, 0x4D1E,
    0x5D7F, 0x659F, 0x6DDF, 0x75FF, 0x75FF, 0xBF5F, 0x5351, 0x0045, 0x0929, 0x6D5C, 0x349D, 0x2BB8, 0x2376, 0x1B15, 0x23F9, 0x5D7E,
    0x012B, 0x0064, 0x0375, 0x018C, 0x00A6, 0x018D, 0x0250, 0x0043, 0x0169, 0x01CC, 0x0064, 0x018D, 0x00E8, 0x0000, 0x0148, 0x01EC,
    0x0000, 0x02D1, 0x0063, 0x01EC, 0x01CB, 0x00A5, 0x0000, 0x0042, 0x0000, 0x00C6, 0x0108, 0x0000, 0x0020, 0x0000, 0x0000, 0x0000,
    0x0000, 0x0000, 0x0000, 0x0084, 0x0021, 0x0000, 0x0021, 0x0000, 0x0000, 0x0000, 0x0021, 0x0042, 0x0083, 0x0062, 0x01CB, 0x0042,
    0x00A4, 0x0021, 0x0021, 0x0021, 0x0042, 0x0042, 0x0021, 0x0129, 0x0022, 0x0127, 0x04BB, 0x0128, 0x020B, 0x0084, 0x00A5, 0x012D,
    0x0318, 0x029C, 0x3E5F, 0x5D19, 0x00A9, 0x00E7, 0x00C6, 0x00E7, 0x0108, 0x00C9, 0x3BD7, 0x763F, 0x553E, 0xAEFF, 0x32D1, 0x0065,
    0x00C6, 0x0023, 0x6CB8, 0x4D7F, 0x3C9C, 0x4CFE, 0x4D1E, 0x4D1E, 0x559F, 0x9E7F, 0x1149, 0x0065, 0x2A6F, 0x453D, 0x1B57, 0x2314,
    0x2314, 0x0AB3, 0x3CDB, 0x4439, 0x00EA, 0x0086, 0x0356, 0x0275, 0x00C7, 0x0149, 0x02B1, 0x0022, 0x00C5, 0x1312, 0x0084, 0x018C,
    0x00C8, 0x0000, 0x00C5, 0x0107, 0x0000, 0x00E7, 0x0042, 0x00C5, 0x00C6, 0x00A4, 0x0000, 0x0041, 0x0021, 0x0021, 0x0021, 0x0000,
    0x0000, 0x0000, 0x0000, 0x0000, 0x0000, 0x0000, 0x0000, 0x0063, 0x0021, 0x0021, 0x0041, 0x0020, 0x0000, 0x0021, 0x0021, 0x0020,
    0x0021, 0x0042, 0x0290, 0x0042, 0x0189, 0x0083, 0x0042, 0x0021, 0x0021, 0x0042, 0x0021, 0x0149, 0x0042, 0x00C5, 0x0395, 0x00E7,
    0x020B, 0x0043, 0x014B, 0x3B97, 0x2D5E, 0x045F, 0x6EFF, 0x22D2, 0x00A7, 0x00C6, 0x00C6, 0x00E7, 0x00C7, 0x0108, 0x010A, 0x4C79,
    0x559F, 0x4D1E, 0x967F, 0x19AD, 0x00A6, 0x0064, 0x1969, 0x75FE, 0x349D, 0x3C5B, 0x3C7B, 0x3C7C, 0x453F, 0x64D8, 0x0085, 0x00A7,
    0x43F6, 0x2C19, 0x1AB3, 0x1AD3, 0x1AB2, 0x0A93, 0x5DBE, 0x1251, 0x010A, 0x00C7, 0x0271, 0x018D, 0x0064, 0x00A5, 0x01AB, 0x0042,
    0x0128, 0x1313, 0x00E8, 0x018D, 0x00A6, 0x0000, 0x0127, 0x01AA, 0x0000, 0x01ED, 0x0042, 0x00C6, 0x0107, 0x00E6, 0x0000, 0x0063,
    0x0021, 0x0042, 0x0063, 0x0000, 0x0000, 0x0000, 0x0000, 0x0000, 0x0000, 0x0000, 0x0000, 0x0083, 0x0021, 0x0021, 0x0041, 0x0021,
    0x0000, 0x0000, 0x0021, 0x0041, 0x0041, 0x0021, 0x0106, 0x0001, 0x0148, 0x0063, 0x0042, 0x0021, 0x0021, 0x0021, 0x0042, 0x0129,
    0x0043, 0x00A5, 0x12D2, 0x00A5, 0x00A4, 0x00C7, 0x018E, 0x1A51, 0x0B9D, 0x0DBF, 0x6E5D, 0x012B, 0x00C6, 0x00A6, 0x00A6, 0x00C7,
    0x00C6, 0x00E8, 0x0108, 0x012B, 0x5D1C, 0x3CDE, 0x4D3E, 0x7DBC, 0x00E9, 0x00A6, 0x0003, 0x5C15, 0x559F, 0x2BFA, 0x341A, 0x2C1A,
    0x4D5E, 0x3B10, 0x0023, 0x0929, 0x4CBA, 0x12F4, 0x1A91, 0x1291, 0x0A30, 0x1B76, 0x659D, 0x012D, 0x012A, 0x0086, 0x12F3, 0x0108,
    0x0022, 0x0063, 0x018A, 0x0042, 0x0128, 0x00C6, 0x0064, 0x016C, 0x0085, 0x0000, 0x0168, 0x020C, 0x0000, 0x020F, 0x0063, 0x0107,
    0x018B, 0x0107, 0x0000, 0x00E7, 0x0063, 0x00C6, 0x012A, 0x0000, 0x0021, 0x0000, 0x0000, 0x0000, 0x0000, 0x0000, 0x0000, 0x0042,
    0x0020, 0x0021, 0x0021, 0x0020, 0x0000, 0x0021, 0x0021, 0x0021, 0x0021, 0x0041, 0x0169, 0x0021, 0x0127, 0x0042, 0x00C6, 0x0084,
    0x0021, 0x0021, 0x0021, 0x0129, 0x0042, 0x0128, 0x14FC, 0x00C5, 0x0043, 0x0109, 0x014A, 0x01D3, 0x041E, 0x4F3F, 0x5478, 0x00E9,
    0x00E7, 0x00C6, 0x00C6, 0x00C7, 0x00C7, 0x0108, 0x0108, 0x00E8, 0x11CE, 0x5D5D, 0x241B, 0x5D9F, 0x4BB4, 0x0065, 0x0044, 0x324D,
    0x75FF, 0x23DA, 0x2BD9, 0x23DA, 0x5D5D, 0x1968, 0x0023, 0x2A8F, 0x3C59, 0x0A2F, 0x1291, 0x124F, 0x01CF, 0x44DA, 0x3C9C, 0x010D,
    0x014C, 0x00E9, 0x0292, 0x00E6, 0x0022, 0x0083, 0x01AB, 0x0022, 0x0107, 0x0021, 0x00A6, 0x016C, 0x00C7, 0x0000, 0x00E6, 0x0169,
    0x0000, 0x0128, 0x0021, 0x0128, 0x00E7, 0x0083, 0x0000, 0x00E7, 0x0083, 0x00A6, 0x0109, 0x0000, 0x0042, 0x0042, 0x0021, 0x0000,
    0x0000, 0x0000, 0x0000, 0x0083, 0x0021, 0x0000, 0x0021, 0x0000, 0x0021, 0x0021, 0x0021, 0x0021, 0x0000, 0x0063, 0x02F2, 0x0063,
    0x00A4, 0x0021, 0x0107, 0x00A4, 0x0021, 0x0021, 0x0021, 0x014A, 0x0022, 0x0128, 0x1CFC, 0x00C5, 0x0063, 0x0063, 0x016D, 0x12D7,
    0x155E, 0x779F, 0x12B5, 0x012B, 0x0109, 0x00E8, 0x00E8, 0x00E9, 0x00E8, 0x0109, 0x00E8, 0x0108, 0x00A7, 0x1A50, 0x4D1C, 0x241B,
    0x651B, 0x00C6, 0x0044, 0x2A0B, 0x7E1F, 0x23FA, 0x2377, 0x241B, 0x5478, 0x0064, 0x0065, 0x43F6, 0x1B14, 0x09ED, 0x0A0E, 0x09ED,
    0x0231, 0x6DBE, 0x137A, 0x016C, 0x00A7, 0x0043, 0x0250, 0x00E7, 0x0022, 0x0084, 0x0128, 0x0042, 0x0127, 0x0000, 0x0043, 0x014C,
    0x0084, 0x0000, 0x0106, 0x0148, 0x0000, 0x0250, 0x0062, 0x0107, 0x00A5, 0x0000, 0x0000, 0x00C6, 0x0083, 0x00C6, 0x0129, 0x0000,
    0x0085, 0x00E7, 0x0021, 0x0000, 0x0000, 0x0000, 0x0000, 0x0062, 0x0021, 0x0020, 0x0021, 0x0021, 0x0000, 0x0021, 0x0042, 0x0021,
    0x0021, 0x0042, 0x0169, 0x0021, 0x01EC, 0x0083, 0x00E6, 0x00A5, 0x0064, 0x0064, 0x0021, 0x014A, 0x00A5, 0x00E7, 0x1B15, 0x00A5,
    0x0042, 0x00A6, 0x01AD, 0x01D4, 0x255E, 0x7F1F, 0x0BBC, 0x139B, 0x12F7, 0x12B5, 0x12B4, 0x12D5, 0x12D6, 0x12D5, 0x12D4, 0x0AB5,
    0x12D5, 0x0A32, 0x445B, 0x34DD, 0x54BA, 0x00A5, 0x0044, 0x42CE, 0x7E1F, 0x1BB9, 0x1336, 0x34BD, 0x3B10, 0x0002, 0x1149, 0x4C79,
    0x020F, 0x09CC, 0x09AC, 0x018C, 0x2376, 0x657D, 0x0213, 0x016C, 0x00E8, 0x0086, 0x0291, 0x00A5, 0x0021, 0x00C6, 0x0107, 0x00A5,
    0x0129, 0x0021, 0x0063, 0x016C, 0x0063, 0x0000, 0x0168, 0x022D, 0x0000, 0x020F, 0x0042, 0x0129, 0x00C7, 0x0000, 0x0000, 0x00C6,
    0x0063, 0x00A5, 0x0129, 0x0000, 0x00C6, 0x0109, 0x0021, 0x0000, 0x0000, 0x0000, 0x0000, 0x0083, 0x0021, 0x0000, 0x0062, 0x0041,
    0x0021, 0x0042, 0x0021, 0x0021, 0x0021, 0x0041, 0x0168, 0x0000, 0x0189, 0x0062, 0x00C6, 0x0084, 0x0021, 0x0084, 0x0084, 0x01AB,
    0x00A5, 0x0929, 0x2BF7, 0x0064, 0x0042, 0x0085, 0x014A, 0x0276, 0x4DFF, 0x9F7F, 0x7E9F, 0x7E9F, 0x867F, 0x7E5F, 0x7E5F, 0x867F,
    0x7E7F, 0x867F, 0x869F, 0x7E7F, 0x869F, 0x867F, 0x7E3E, 0x65DE, 0x3AF0, 0x0043, 0x0045, 0x6C76, 0x659F, 0x1357, 0x0B37, 0x4D1C,
    0x1968, 0x0002, 0x328F, 0x33D7, 0x018C, 0x098B, 0x098B, 0x014C, 0x555C, 0x3C18, 0x02D4, 0x01ED, 0x00C7, 0x0064, 0x0B14, 0x00A5,
    0x0021, 0x0063, 0x00C5, 0x0063, 0x018D, 0x0084, 0x0109, 0x00E8, 0x0041, 0x0021, 0x0107, 0x01CB, 0x0000, 0x0084, 0x0021, 0x0108,
    0x00C6, 0x0021, 0x0000, 0x00E7, 0x0083, 0x00A6, 0x0129, 0x0000, 0x0085, 0x00C6, 0x0021, 0x0000, 0x0000, 0x0000, 0x0000, 0x0063,
    0x0021, 0x0000, 0x0083, 0x0042, 0x0041, 0x0021, 0x0000, 0x0021, 0x0021, 0x0021, 0x01CB, 0x0021, 0x00A5, 0x0041, 0x00E6, 0x0084,
    0x0021, 0x0063, 0x0064, 0x018B, 0x0021, 0x00A5, 0x0314, 0x0064, 0x00C5, 0x0084, 0x00C7, 0x014B, 0x0A75, 0x0A52, 0x096B, 0x08E7,
    0x08E6, 0x08E6, 0x08E6, 0x10E6, 0x08E5, 0x08E6, 0x08E6, 0x08E6, 0x10E6, 0x08E6, 0x10E6, 0x1106, 0x0063, 0x0084, 0x0909, 0x9E7E,
    0x2C5B, 0x12D5, 0x1398, 0x5498, 0x0063, 0x0064, 0x4BD5, 0x1270, 0x0149, 0x014A, 0x014A, 0x0251, 0x763F, 0x0A33, 0x01F0, 0x016A,
    0x0147, 0x0022, 0x01EF, 0x00A5, 0x0021, 0x0063, 0x0128, 0x0000, 0x00C7, 0x0063, 0x016C, 0x0021, 0x00A5, 0x0043, 0x0149, 0x022E,
    0x0000, 0x0062, 0x0000, 0x0108, 0x00A5, 0x0042, 0x0000, 0x00E7, 0x0084, 0x00A6, 0x0129, 0x0000, 0x0042, 0x0063, 0x0021, 0x0000,
    0x0000, 0x0000, 0x0000, 0x0063, 0x0021, 0x0000, 0x00C6, 0x0042, 0x0000, 0x0000, 0x0021, 0x0041, 0x0021, 0x0021, 0x022D, 0x0041,
    0x00A4, 0x0042, 0x00C5, 0x0063, 0x0021, 0x0042, 0x0000, 0x016A, 0x0063, 0x08E6, 0x3458, 0x0085, 0x020C, 0x0189, 0x0042, 0x0085,
    0x014A, 0x00C7, 0x0064, 0x0063, 0x0042, 0x0042, 0x0022, 0x0043, 0x0022, 0x0044, 0x0044, 0x0042, 0x0042, 0x0043, 0x0043, 0x0042,
    0x00A5, 0x0024, 0x6C35, 0x763F, 0x0B17, 0x0294, 0x2C7C, 0x4330, 0x0001, 0x1169, 0x4417, 0x014A, 0x096A, 0x0149, 0x012B, 0x3CFB,
    0x5D9F, 0x0130, 0x020D, 0x018A, 0x00C6, 0x0084, 0x0A93, 0x0084, 0x0062, 0x0084, 0x014A, 0x0021, 0x0021, 0x0063, 0x016B, 0x0043,
    0x00A5, 0x0000, 0x0107, 0x01CC, 0x0000, 0x0063, 0x0000, 0x00C7, 0x0085, 0x0000, 0x0000, 0x00C6, 0x0083, 0x00A6, 0x0129, 0x0000,
    0x0021, 0x0042, 0x0021, 0x0000, 0x0000, 0x0000, 0x0000, 0x0063, 0x0021, 0x0000, 0x0107, 0x0063, 0x0000, 0x0000, 0x0000, 0x0041,
    0x0020, 0x0021, 0x0063, 0x0021, 0x0084, 0x0021, 0x00E6, 0x0084, 0x0021, 0x0063, 0x0084, 0x020E, 0x00A5, 0x0108, 0x1275, 0x0064,
    0x0106, 0x00E6, 0x0043, 0x00C8, 0x01EF, 0x012A, 0x00A6, 0x00E7, 0x0084, 0x0064, 0x0084, 0x0085, 0x0063, 0x014B, 0x0109, 0x0084,
    0x00A6, 0x00C6, 0x00C6, 0x00C6, 0x0086, 0x220E, 0xAEFF, 0x13DA, 0x0AB4, 0x02B5, 0x553D, 0x1948, 0x0003, 0x32F1, 0x2B33, 0x0129,
    0x0948, 0x00E9, 0x02F5, 0x8F1F, 0x12B7, 0x00A9, 0x014A, 0x0108, 0x0084, 0x0063, 0x0BF8, 0x00E7, 0x0084, 0x0063, 0x01AC, 0x0064,
    0x0065, 0x0044, 0x01AC, 0x0043, 0x0062, 0x0000, 0x0127, 0x0A0D, 0x0001, 0x0042, 0x0000, 0x0108, 0x00C6, 0x0042, 0x0000, 0x00E7,
    0x0084, 0x00A5, 0x012A, 0x0000, 0x0021, 0x0021, 0x0000, 0x0000, 0x0000, 0x0000, 0x0000, 0x0063, 0x0021, 0x0000, 0x00C6, 0x0063,
    0x0000, 0x0000, 0x0021, 0x0042, 0x0000, 0x0021, 0x0127, 0x0000, 0x00C5, 0x0042, 0x00C6, 0x0083, 0x0021, 0x0042, 0x0021, 0x0108,
    0x0021, 0x0084, 0x3C7A, 0x0084, 0x018A, 0x0148, 0x0022, 0x014B, 0x0251, 0x012A, 0x00C7, 0x012A, 0x0085, 0x0064, 0x0064, 0x0086,
    0x00A7, 0x016D, 0x010A, 0x0085, 0x00C8, 0x00C9, 0x00CA, 0x00CA, 0x014E, 0xA65E, 0x34FD, 0x02B7, 0x0255, 0x13DB, 0x5436, 0x0023,
    0x00C8, 0x4419, 0x01F1, 0x012C, 0x016E, 0x0B37, 0x973F, 0x4C1A, 0x00EC, 0x00A7, 0x018C, 0x014A, 0x0084, 0x0042, 0x0129, 0x00A6,
    0x00A7, 0x00A7, 0x0129, 0x0000, 0x11CC, 0x1250, 0x020D, 0x0021, 0x0083, 0x00C5, 0x0168, 0x0A8F, 0x0001, 0x0041, 0x0000, 0x0084,
    0x0062, 0x0042, 0x0000, 0x0084, 0x0042, 0x00C6, 0x012A, 0x0000, 0x0021, 0x0021, 0x0000, 0x0000, 0x0000, 0x0000, 0x0000, 0x0000,
    0x0000, 0x0000, 0x00A5, 0x0062, 0x0000, 0x0000, 0x0021, 0x0042, 0x0000, 0x0021, 0x018A, 0x0042, 0x00A5, 0x0042, 0x00E6, 0x0083,
    0x0000, 0x0021, 0x0042, 0x0021, 0x0021, 0x0043, 0x0376, 0x0064, 0x01EC, 0x0169, 0x0000, 0x0022, 0x014A, 0x00E7, 0x0064, 0x01CE,
    0x00C7, 0x00A5, 0x00C6, 0x014A, 0x014B, 0x0A71, 0x1271, 0x1210, 0x1294, 0x1AF7, 0x23B9, 0x23BB, 0x963E, 0x773F, 0x147E, 0x1C7E,
    0x1C7E, 0x5DFF, 0x21AA, 0x0044, 0x22F4, 0x561F, 0x1C5B, 0x2CDC, 0x5E3F, 0x9F5F, 0x5439, 0x014F, 0x01AF, 0x0065, 0x01AC, 0x018C,
    0x0107, 0x0043, 0x0AD2, 0x0084, 0x118C, 0x2B15, 0x0044, 0x0043, 0x0909, 0x094A, 0x0108, 0x0042, 0x0084, 0x022E, 0x00A5, 0x012A,
    0x0021, 0x0042, 0x0000, 0x018B, 0x012A, 0x0042, 0x0001, 0x0108, 0x00A5, 0x00C6, 0x016B, 0x0000, 0x0021, 0x0000, 0x0000, 0x0000,
    0x0000, 0x0000, 0x0000, 0x0000, 0x0000, 0x0000, 0x00E7, 0x0063, 0x0000, 0x0000, 0x0021, 0x0042, 0x0020, 0x0000, 0x01EC, 0x0083,
    0x00A4, 0x0042, 0x00E6, 0x0083, 0x0000, 0x0042, 0x012B, 0x00C6, 0x0000, 0x0064, 0x13B5, 0x0084, 0x00E6, 0x00A5, 0x0042, 0x0022,
    0x0149, 0x00C6, 0x0065, 0x0AD4, 0x00C7, 0x00A5, 0x0128, 0x01ED, 0x01EC, 0x1B55, 0x2B97, 0x2B78, 0x349D, 0x44FE, 0x4D9E, 0x5DFE,
    0x6D7C, 0x44BB, 0x5CFC, 0x54DB, 0x5CFB, 0x3B75, 0x0044, 0x00E9, 0x24BD, 0x6E3F, 0x6DDE, 0x759D, 0x5C99, 0x1A73, 0x00A8, 0x00A4,
    0x00E8, 0x0063, 0x014B, 0x014B, 0x00E7, 0x0022, 0x02D5, 0x00C5, 0x0086, 0x01CF, 0x0084, 0x0022, 0x0087, 0x0085, 0x018C, 0x0021,
    0x0021, 0x0085, 0x00A6, 0x016B, 0x0000, 0x0042, 0x0000, 0x01EF, 0x018D, 0x0021, 0x0000, 0x00E7, 0x0084, 0x00E7, 0x016B, 0x0000,
    0x0021, 0x0000, 0x0000, 0x0000, 0x0000, 0x0000, 0x0000, 0x0000, 0x0000, 0x0000, 0x0108, 0x0084, 0x0000, 0x0000, 0x0021, 0x0042,
    0x0000, 0x0020, 0x0148, 0x0042, 0x0084, 0x0021, 0x00E6, 0x0083, 0x0000, 0x0043, 0x0042, 0x0042, 0x0000, 0x0043, 0x098B, 0x0021,
    0x022E, 0x0169, 0x0042, 0x0042, 0x016A, 0x00E7, 0x0086, 0x1336, 0x00C6, 0x00A6, 0x0085, 0x00C7, 0x0065, 0x00A7, 0x00C8, 0x00A8,
    0x016D, 0x014D, 0x016F, 0x00C9, 0x014C, 0x0024, 0x0045, 0x0045, 0x0024, 0x0043, 0x0022, 0x0108, 0x0211, 0x010B, 0x00C9, 0x0046,
    0x0024, 0x0064, 0x0084, 0x0109, 0x00A5, 0x0021, 0x01EE, 0x018B, 0x0065, 0x0042, 0x018C, 0x00A6, 0x0085, 0x00C7, 0x0023, 0x014B,
    0x0210, 0x00A6, 0x02D1, 0x0000, 0x0042, 0x00A6, 0x00A5, 0x016A, 0x0000, 0x0042, 0x0000, 0x00E6, 0x00C5, 0x0063, 0x0000, 0x00E7,
    0x0084, 0x00C6, 0x014B, 0x0000, 0x0021, 0x0000, 0x0000, 0x0000, 0x0000, 0x0000, 0x0000, 0x0000, 0x0000, 0x0000, 0x00A4, 0x0042,
    0x0000, 0x0000, 0x0021, 0x0042, 0x0000, 0x0000, 0x0149, 0x0063, 0x0084, 0x0042, 0x00A5, 0x0063, 0x0000, 0x0000, 0x0084, 0x0042,
    0x0000, 0x0084, 0x012A, 0x0000, 0x016A, 0x00E6, 0x0084, 0x0042, 0x0128, 0x00C6, 0x0085, 0x12B4, 0x00C7, 0x00C7, 0x00A6, 0x00E9,
    0x010A, 0x00C6, 0x00C6, 0x0085, 0x016B, 0x0129, 0x018B, 0x00A5, 0x01EE, 0x0041, 0x0062, 0x0063, 0x0063, 0x0063, 0x00A5, 0x00A6,
    0x00E7, 0x0083, 0x01CE, 0x00C6, 0x0042, 0x00A6, 0x0021, 0x0232, 0x0109, 0x0000, 0x0129, 0x00E7, 0x0085, 0x0043, 0x02D3, 0x014C,
    0x010A, 0x0064, 0x0044, 0x010C, 0x012B, 0x00A6, 0x01AC, 0x0043, 0x0062, 0x00E7, 0x00E6, 0x018A, 0x0022, 0x0021, 0x0000, 0x0108,
    0x00C6, 0x0041, 0x0000, 0x0042, 0x0021, 0x00C6, 0x012A, 0x0000, 0x0021, 0x0000, 0x0000, 0x0000, 0x0000, 0x0000, 0x0000, 0x0000,
    0x0000, 0x0000, 0x0063, 0x0042, 0x0000, 0x0000, 0x0021, 0x0042, 0x0021, 0x0000, 0x016A, 0x0084, 0x0084, 0x0042, 0x0063, 0x0042,
    0x0021, 0x0000, 0x016B, 0x00E7, 0x0000, 0x0063, 0x016B, 0x0021, 0x0128, 0x00C5, 0x00A6, 0x0043, 0x0108, 0x00A5, 0x0084, 0x1B55,
    0x00E8, 0x0084, 0x0064, 0x0085, 0x0042, 0x00A6, 0x00A5, 0x0064, 0x01AC, 0x0129, 0x0085, 0x0084, 0x012A, 0x0043, 0x0063, 0x0064,
    0x0043, 0x0063, 0x00E7, 0x00A6, 0x0084, 0x0063, 0x0252, 0x00C7, 0x0064, 0x014C, 0x0043, 0x0108, 0x0084, 0x0001, 0x00E8, 0x00C6,
    0x00A6, 0x0043, 0x01CD, 0x0063, 0x0043, 0x00C7, 0x00A6, 0x098E, 0x09F0, 0x00A6, 0x018C, 0x0001, 0x0042, 0x0085, 0x0149, 0x0250,
    0x0000, 0x0021, 0x0000, 0x0108, 0x0108, 0x0042, 0x0000, 0x0063, 0x0041, 0x0042, 0x0084, 0x0000, 0x0000, 0x0000, 0x0000, 0x0000,
    0x0000, 0x0000, 0x0000, 0x0000, 0x0000, 0x0000, 0x0042, 0x0021, 0x0000, 0x0000, 0x0021, 0x0063, 0x0021, 0x0021, 0x0969, 0x0063,
    0x0084, 0x0042, 0x0021, 0x0021, 0x0021, 0x0021, 0x0064, 0x0063, 0x0020, 0x0063, 0x0128, 0x0000, 0x01ED, 0x0149, 0x0084, 0x0042,
    0x00E7, 0x00A5, 0x0022, 0x0A50, 0x00A5, 0x0063, 0x0064, 0x0042, 0x0063, 0x00A6, 0x00A5, 0x0084, 0x0128, 0x0107, 0x00E8, 0x0063,
    0x014A, 0x0043, 0x0063, 0x0063, 0x00C5, 0x0063, 0x0043, 0x00C6, 0x0084, 0x0064, 0x03F8, 0x0148, 0x0086, 0x014C, 0x0043, 0x0108,
    0x0084, 0x0021, 0x012A, 0x00C7, 0x0085, 0x0021, 0x0270, 0x00A4, 0x0000, 0x014B, 0x016F, 0x1BDA, 0x2C9C, 0x0045, 0x016C, 0x0021,
    0x0042, 0x00E7, 0x00C5, 0x018B, 0x0000, 0x0041, 0x0000, 0x00E6, 0x00C6, 0x0042, 0x0000, 0x00A6, 0x00A5, 0x0022, 0x0064, 0x0000,
    0x0000, 0x0000, 0x0000, 0x0000, 0x0000, 0x0000, 0x0000, 0x0000, 0x0000, 0x0000, 0x0021, 0x0000, 0x0000, 0x0000, 0x0021, 0x0042,
    0x0000, 0x0000, 0x0083, 0x0021, 0x00A4, 0x0063, 0x0000, 0x0021, 0x0021, 0x0000, 0x0108, 0x014A, 0x0021, 0x0042, 0x0108, 0x0000,
    0x00C6, 0x00A4, 0x00A5, 0x0042, 0x00E7, 0x0084, 0x0021, 0x0A0F, 0x0084, 0x0063, 0x0021, 0x00C7, 0x010A, 0x014B, 0x00A6, 0x0063,
    0x0108, 0x00C6, 0x0084, 0x0063, 0x020D, 0x0042, 0x0063, 0x0084, 0x018B, 0x0064, 0x0063, 0x00A6, 0x00C8, 0x0064, 0x04BC, 0x01AA,
    0x0064, 0x01AD, 0x0000, 0x01AD, 0x00A5, 0x0043, 0x016C, 0x00A6, 0x0064, 0x0042, 0x0314, 0x00A5, 0x0043, 0x00E8, 0x00A6, 0x00A9,
    0x00A9, 0x0042, 0x0064, 0x0109, 0x0129, 0x0042, 0x0062, 0x0128, 0x0021, 0x0041, 0x0000, 0x00E7, 0x00E7, 0x0042, 0x0000, 0x012B,
    0x00E9, 0x00C7, 0x018D, 0x0000, 0x0000, 0x0000, 0x0000, 0x0000, 0x0000, 0x0000, 0x0000, 0x0000, 0x0000, 0x0000, 0x0000, 0x0000,
    0x0000, 0x0000, 0x0042, 0x0063, 0x0000, 0x0000, 0x0128, 0x0063, 0x00A5, 0x0084, 0x0021, 0x0021, 0x0042, 0x0042, 0x0063, 0x0063,
    0x0021, 0x0021, 0x014A, 0x0021, 0x00C5, 0x00A5, 0x00E7, 0x0042, 0x00E6, 0x0084, 0x0021, 0x016A, 0x0042, 0x0021, 0x0021, 0x00C7,
    0x00A5, 0x0084, 0x0084, 0x0084, 0x016A, 0x0107, 0x0108, 0x0043, 0x018B, 0x0042, 0x0063, 0x0064, 0x00C6, 0x0084, 0x0084, 0x00A5,
    0x0085, 0x0022, 0x0291, 0x0107, 0x0064, 0x016B, 0x0021, 0x0128, 0x0084, 0x0021, 0x014B, 0x00E7, 0x0042, 0x0021, 0x01AB, 0x0062,
    0x0042, 0x00A6, 0x00A6, 0x00A7, 0x00E9, 0x0043, 0x00C6, 0x00C7, 0x0084, 0x0000, 0x0083, 0x016B, 0x0021, 0x0021, 0x0000, 0x00A5,
    0x00C6, 0x0042, 0x0000, 0x022F, 0x01CD, 0x00A6, 0x018D, 0x0000, 0x0000, 0x0000, 0x0000, 0x0000, 0x0000, 0x0000, 0x0000, 0x0000,
    0x0000, 0x0000, 0x0000, 0x0000, 0x0000, 0x0000, 0x0021, 0x0042, 0x0000, 0x0000, 0x0128, 0x0062, 0x00C5, 0x0063, 0x0000, 0x0021,
    0x0022, 0x0042, 0x0021, 0x0042, 0x0043, 0x0042, 0x00A6, 0x0001, 0x0129, 0x0128, 0x00A5, 0x0042, 0x0129, 0x00A5, 0x0021, 0x00E7,
    0x0064, 0x0041, 0x0021, 0x0085, 0x0084, 0x0042, 0x0063, 0x0043, 0x018A, 0x00E6, 0x0064, 0x0043, 0x018B, 0x0043, 0x0043, 0x00E6,
    0x02F2, 0x00E8, 0x00E7, 0x01CE, 0x0084, 0x0021, 0x0250, 0x00A5, 0x0086, 0x01AE, 0x0022, 0x016B, 0x00A5, 0x0000, 0x0108, 0x00C6,
    0x0064, 0x0021, 0x02B2, 0x00A4, 0x0000, 0x0084, 0x00A6, 0x0043, 0x0043, 0x0043, 0x00C6, 0x0021, 0x0000, 0x0000, 0x0063, 0x0108,
    0x0021, 0x0042, 0x0000, 0x00E7, 0x0108, 0x0042, 0x0000, 0x01EE, 0x01AD, 0x0063, 0x0129, 0x0000, 0x0000, 0x0000, 0x0000, 0x0000,
    0x0000, 0x0000, 0x0000, 0x0000, 0x0000, 0x0000, 0x0000, 0x0000, 0x0000, 0x0000, 0x0000, 0x0042, 0x0000, 0x0000, 0x00A5, 0x0042,
    0x00A5, 0x0063, 0x0063, 0x00A6, 0x0084, 0x0043, 0x0042, 0x0043, 0x0085, 0x0043, 0x00E8, 0x0021, 0x00C6, 0x00A5, 0x00A5, 0x0022,
    0x0129, 0x00A5, 0x0021, 0x0109, 0x0063, 0x0042, 0x0042, 0x0063, 0x0042, 0x0043, 0x0064, 0x0064, 0x016B, 0x0107, 0x00A5, 0x0063,
    0x018B, 0x0063, 0x0043, 0x0148, 0x0459, 0x022F, 0x0109, 0x018C, 0x00A5, 0x0001, 0x02F2, 0x00E6, 0x0084, 0x01EF, 0x0000, 0x01CE,
    0x00C6, 0x0042, 0x014A, 0x00A5, 0x0085, 0x0021, 0x022F, 0x00A4, 0x0021, 0x00A5, 0x0084, 0x0084, 0x0021, 0x0021, 0x0000, 0x0000,
    0x0021, 0x0000, 0x0063, 0x00C6, 0x0021, 0x0021, 0x0000, 0x00A4, 0x00C6, 0x0063, 0x0000, 0x01CF, 0x016C, 0x0084, 0x018D, 0x0000,
    0x0000, 0x0000, 0x0000, 0x0000, 0x0000, 0x0000, 0x0000, 0x0000, 0x0000, 0x0000, 0x0000, 0x0000, 0x0000, 0x0000, 0x0021, 0x0042,
    0x0020, 0x0000, 0x00E6, 0x0063, 0x00A5, 0x0084, 0x00E9, 0x0A73, 0x01AE, 0x00A6, 0x0084, 0x0063, 0x00E8, 0x018F, 0x01AE, 0x0042,
    0x0042, 0x0021, 0x0084, 0x0022, 0x0129, 0x00A5, 0x0021, 0x016B, 0x0085, 0x0042, 0x0063, 0x0907, 0x00A5, 0x00A6, 0x0063, 0x0043,
    0x016A, 0x00E6, 0x00A5, 0x0042, 0x0149, 0x0043, 0x0064, 0x00E6, 0x028F, 0x00C7, 0x0063, 0x0129, 0x0042, 0x0021, 0x01ED, 0x00C5,
    0x0084, 0x016B, 0x0042, 0x0108, 0x0063, 0x0022, 0x0129, 0x00A5, 0x0063, 0x0021, 0x018B, 0x0084, 0x0021, 0x00A5, 0x0084, 0x0063,
    0x00C7, 0x00C6, 0x0084, 0x00C6, 0x0063, 0x0000, 0x0063, 0x0128, 0x0021, 0x0042, 0x0000, 0x00C6, 0x0107, 0x0000, 0x0000, 0x0109,
    0x00E8, 0x00A6, 0x01AD, 0x0000, 0x0000, 0x0000, 0x0000, 0x0000, 0x0000, 0x0000, 0x0000, 0x0000, 0x0000, 0x0000, 0x0000, 0x0021,
    0x0021, 0x0000, 0x0021, 0x0042, 0x0021, 0x0000, 0x0128, 0x0084, 0x0063, 0x0063, 0x0022, 0x0045, 0x0065, 0x0023, 0x00A5, 0x0043,
    0x0044, 0x1B79, 0x01F2, 0x0084, 0x0084, 0x0085, 0x00C6, 0x0021, 0x0129, 0x0084, 0x0000, 0x00A5, 0x0063, 0x0064, 0x0063, 0x00E7,
    0x00A5, 0x0084, 0x0063, 0x0001, 0x0128, 0x00C5, 0x0084, 0x0042, 0x016A, 0x0042, 0x0064, 0x0084, 0x016A, 0x0042, 0x0021, 0x0000,
    0x0022, 0x0021, 0x0AD1, 0x00A5, 0x00C6, 0x0B58, 0x0064, 0x01AE, 0x00C6, 0x0021, 0x00C6, 0x0084, 0x0042, 0x0000, 0x0292, 0x00A5,
    0x0000, 0x00E7, 0x00A4, 0x0021, 0x0063, 0x0063, 0x0042, 0x0042, 0x0063, 0x0021, 0x0084, 0x0129, 0x0000, 0x0042, 0x0000, 0x0084,
    0x00A4, 0x0021, 0x0000, 0x0109, 0x00E8, 0x0085, 0x018D, 0x0000, 0x0000, 0x0000, 0x0000, 0x0000, 0x0000, 0x0000, 0x0000, 0x0000,
    0x0000, 0x0000, 0x0000, 0x0021, 0x0021, 0x0000, 0x0021, 0x0042, 0x0021, 0x0000, 0x0084, 0x0063, 0x0083, 0x0042, 0x1128, 0x42EF,
    0x2A2D, 0x220C, 0x0086, 0x1169, 0x1969, 0x00C8, 0x01F2, 0x010A, 0x00C6, 0x00A6, 0x0108, 0x0021, 0x016A, 0x00A4, 0x0000, 0x0063,
    0x0063, 0x0042, 0x0000, 0x0021, 0x0042, 0x0042, 0x00A5, 0x0000, 0x0149, 0x00E6, 0x0085, 0x0041, 0x018A, 0x0063, 0x0064, 0x0128,
    0x0356, 0x0021, 0x0042, 0x0021, 0x0063, 0x0022, 0x0271, 0x00E7, 0x00E6, 0x359E, 0x00A7, 0x018D, 0x00C6, 0x0021, 0x00E7, 0x0084,
    0x0042, 0x0042, 0x016B, 0x0084, 0x0020, 0x00E7, 0x0108, 0x0063, 0x0041, 0x0000, 0x0042, 0x0000, 0x0063, 0x0021, 0x0063, 0x00C6,
    0x0000, 0x0042, 0x0000, 0x00C5, 0x0107, 0x0000, 0x0000, 0x014B, 0x0109, 0x0084, 0x016C, 0x0000, 0x0000, 0x0000, 0x0000, 0x0000,
    0x0000, 0x0000, 0x0000, 0x0000, 0x0000, 0x0000, 0x0000, 0x0000, 0x0000, 0x0000, 0x0021, 0x0043, 0x0021, 0x0021, 0x0129, 0x00A5,
    0x00E7, 0x0023, 0x6C13, 0x9DBB, 0x9559, 0x7497, 0x5BB2, 0x84D6, 0x29A9, 0x0022, 0x00C8, 0x00A5, 0x0085, 0x00C6, 0x00E8, 0x0043,
    0x00E6, 0x0063, 0x0021, 0x00A6, 0x0043, 0x0084, 0x0021, 0x0063, 0x0043, 0x0021, 0x0022, 0x0000, 0x00E7, 0x00A5, 0x00C6, 0x0042,
    0x0129, 0x0063, 0x00A5, 0x0063, 0x01AB, 0x0042, 0x0042, 0x0042, 0x0063, 0x0042, 0x00C6, 0x0084, 0x00A5, 0x01CF, 0x0085, 0x00C6,
    0x0063, 0x0064, 0x0129, 0x00A5, 0x0084, 0x0043, 0x0149, 0x0021, 0x0021, 0x00C6, 0x00A5, 0x0042, 0x0021, 0x0021, 0x0042, 0x0021,
    0x0042, 0x0000, 0x0042, 0x00C6, 0x0000, 0x0042, 0x0000, 0x00A5, 0x00C6, 0x0000, 0x0000, 0x00E7, 0x00A6, 0x0085, 0x014B, 0x0000,
    0x0000, 0x0000, 0x0000, 0x0000, 0x0000, 0x0000, 0x0000, 0x0000, 0x0000, 0x0000, 0x0000, 0x0000, 0x0000, 0x0000, 0x0021, 0x0063,
    0x0022, 0x0021, 0x016C, 0x00E9, 0x0109, 0x0044, 0x5BF3, 0x7CD7, 0x8D59, 0x00E8, 0x8D99, 0x5BB2, 0x0000, 0x0085, 0x00A7, 0x0020,
    0x0064, 0x0063, 0x0108, 0x00C7, 0x00C6, 0x0084, 0x0022, 0x0084, 0x0041, 0x0042, 0x0021, 0x0042, 0x0042, 0x0021, 0x0042, 0x0021,
    0x0108, 0x00C6, 0x00C6, 0x0042, 0x018C, 0x0084, 0x00C6, 0x0063, 0x0129, 0x0022, 0x0042, 0x0043, 0x00A6, 0x0064, 0x018B, 0x0084,
    0x0085, 0x01AD, 0x0064, 0x00C6, 0x0042, 0x0085, 0x0109, 0x00A5, 0x0063, 0x0042, 0x014A, 0x0064, 0x0021, 0x00C6, 0x0084, 0x0021,
    0x0042, 0x0021, 0x0021, 0x0021, 0x0063, 0x0000, 0x0063, 0x00E7, 0x0000, 0x0063, 0x0000, 0x0084, 0x00C6, 0x0000, 0x0021, 0x0084,
    0x0064, 0x0042, 0x00A5, 0x0000, 0x0000, 0x0000, 0x0000, 0x0000, 0x0000, 0x0000, 0x0000, 0x0000, 0x0000, 0x0000, 0x0000, 0x0000,
    0x0000, 0x0001, 0x0000, 0x0064, 0x00E8, 0x0001, 0x00C6, 0x0084, 0x0084, 0x0043, 0x2355, 0x33F8, 0x5CB9, 0x0085, 0x2B32, 0x0948,
    0x0022, 0x0063, 0x0085, 0x0042, 0x0063, 0x0042, 0x00A6, 0x00E8, 0x00E7, 0x0043, 0x0043, 0x00C6, 0x0042, 0x0042, 0x0021, 0x0084,
    0x0084, 0x0022, 0x0042, 0x0042, 0x0109, 0x00C6, 0x0108, 0x0042, 0x016B, 0x0085, 0x00C6, 0x00A5, 0x01EF, 0x0042, 0x0063, 0x0084,
    0x00C7, 0x0085, 0x01EF, 0x00E7, 0x0043, 0x0108, 0x0085, 0x0108, 0x0084, 0x0084, 0x014A, 0x00A5, 0x0063, 0x0084, 0x00A5, 0x0042,
    0x0021, 0x0108, 0x0084, 0x0021, 0x0042, 0x0042, 0x0021, 0x0021, 0x0084, 0x0021, 0x0063, 0x00E6, 0x0021, 0x0063, 0x0000, 0x0063,
    0x0084, 0x0021, 0x0022, 0x0064, 0x0042, 0x00C6, 0x018C, 0x0000, 0x0020, 0x0000, 0x0000, 0x0000, 0x0000, 0x0000, 0x0000, 0x0000,
    0x0000, 0x0000, 0x0000, 0x0000, 0x0000, 0x0021, 0x0021, 0x0022, 0x0315, 0x0109, 0x0086, 0x0084, 0x0063, 0x0063, 0x0107, 0x11AA,
    0x0908, 0x0002, 0x0928, 0x0084, 0x0043, 0x0063, 0x0023, 0x0043, 0x0063, 0x0043, 0x0084, 0x00A6, 0x0108, 0x0109, 0x0043, 0x00A5,
    0x0043, 0x0063, 0x0042, 0x0064, 0x0084, 0x0042, 0x0063, 0x0064, 0x012A, 0x00E8, 0x0109, 0x0063, 0x016B, 0x0085, 0x00A6, 0x00A5,
    0x01AD, 0x0063, 0x0064, 0x0045, 0x0024, 0x0043, 0x00A5, 0x0064, 0x0063, 0x0085, 0x0044, 0x0044, 0x0002, 0x00A7, 0x01AF, 0x0084,
    0x0084, 0x0042, 0x0108, 0x0042, 0x0042, 0x00C6, 0x00C6, 0x0021, 0x0043, 0x0063, 0x0042, 0x0042, 0x0085, 0x0022, 0x0042, 0x0043,
    0x0001, 0x0085, 0x0043, 0x0042, 0x0001, 0x0022, 0x0022, 0x0064, 0x0022, 0x016A, 0x02D4, 0x0000, 0x0020, 0x0000, 0x0000, 0x0000,
    0x0000, 0x0000, 0x0000, 0x0000, 0x0000, 0x0000, 0x0000, 0x0000, 0x0000, 0x0000, 0x0021, 0x0001, 0x0909, 0x0AF4, 0x00A7, 0x0085,
    0x0043, 0x0042, 0x0001, 0x0001, 0x0084, 0x324C, 0x08C7, 0x0043, 0x0063, 0x0085, 0x2A0B, 0x1127, 0x0063, 0x0084, 0x0084, 0x00A5,
    0x0108, 0x00C6, 0x0042, 0x0063, 0x0084, 0x0063, 0x0063, 0x0084, 0x0083, 0x0063, 0x0063, 0x0084, 0x0129, 0x0129, 0x018C, 0x00C6,
    0x016B, 0x00A5, 0x00A5, 0x0109, 0x02B6, 0x0043, 0x114A, 0x9D99, 0xCEDC, 0x3A4B, 0x0002, 0x0084, 0x0044, 0x116A, 0x326D, 0x3A6D,
    0x3A4C, 0x2A0C, 0x014C, 0x00A5, 0x0084, 0x0063, 0x0109, 0x0064, 0x0063, 0x00C6, 0x00A4, 0x0084, 0x08E7, 0x00A5, 0x0063, 0x0063,
    0x00C6, 0x0063, 0x0042, 0x29EA, 0x2188, 0x0064, 0x0021, 0x0042, 0x0043, 0x0042, 0x0021, 0x0042, 0x0022, 0x00C7, 0x016D, 0x0000,
    0x0000, 0x0000, 0x0000, 0x0000, 0x0000, 0x0000, 0x0000, 0x0000, 0x0000, 0x0000, 0x0000, 0x0000, 0x0000, 0x0000, 0x0021, 0x0042,
    0x0002, 0x018C, 0x01EE, 0x0002, 0x0022, 0x0042, 0x0021, 0x0042, 0x0022, 0xBE3B, 0xBE3B, 0x0044, 0x0003, 0x7C75, 0xEFBF, 0x1128,
    0x0003, 0x0024, 0x0024, 0x0044, 0x00E7, 0x0024, 0x0043, 0x0084, 0x0044, 0x0043, 0x0044, 0x0004, 0x0004, 0x0004, 0x0023, 0x0064,
    0x0045, 0x0067, 0x00EB, 0x0066, 0x012A, 0x0025, 0x0024, 0x0046, 0x014E, 0x0003, 0x7434, 0xDF1D, 0x8455, 0x21CA, 0x0063, 0x0044,
    0x2A2D, 0xEFBF, 0xFFFF, 0xFFFF, 0xFFFF, 0xCE9B, 0x0002, 0x0024, 0x0024, 0x0004, 0x0086, 0x0085, 0x0023, 0x0024, 0x0000, 0x5350,
    0xA5B9, 0x0004, 0x0002, 0x0002, 0x0024, 0x0002, 0x0002, 0xCEBC, 0x7C53, 0x0001, 0x0062, 0x0021, 0x0043, 0x0042, 0x0021, 0x0042,
    0x0021, 0x00C7, 0x014B, 0x0000, 0x0000, 0x0000, 0x0000, 0x0000, 0x0000, 0x0000, 0x0000, 0x0000, 0x0000, 0x0000, 0x0000, 0x0000,
    0x0000, 0x0000, 0x0000, 0x0022, 0x01AE, 0x016E, 0x0AF4, 0x09AC, 0x014B, 0x0043, 0x0021, 0x0041, 0x0044, 0x116A, 0xF7FF, 0x42F0,
    0x2A0D, 0xFFFF, 0x3A8E, 0x0909, 0x84D6, 0x8CF7, 0x8D17, 0x4B31, 0x00C7, 0x63B3, 0x1107, 0x0022, 0x3A8E, 0x3A8D, 0x198B, 0x84B6,
    0x84D6, 0x8CF7, 0x5330, 0x116B, 0x7CB6, 0x8CF7, 0x84F7, 0x63B2, 0x00E9, 0x7455, 0x9537, 0x9517, 0x63B2, 0x10E9, 0xC67B, 0xADDA,
    0x3A70, 0x00C7, 0x00A5, 0x0003, 0xA598, 0x9D78, 0x218B, 0x324D, 0x2A2D, 0x218A, 0x42CE, 0x7CB6, 0x7C95, 0x7475, 0x21EC, 0x0023,
    0x42CF, 0x8CF6, 0x7413, 0xBE5B, 0x9516, 0x0086, 0x7C94, 0x8CF6, 0x8CF5, 0x5370, 0x0045, 0xCEDD, 0x5B70, 0x0001, 0x0062, 0x0063,
    0x0042, 0x0022, 0x0043, 0x0043, 0x0043, 0x0085, 0x00C7, 0x0000, 0x0000, 0x0000, 0x0000, 0x0000, 0x0000, 0x0000, 0x0000, 0x0000,
    0x0000, 0x0000, 0x0000, 0x0000, 0x0000, 0x0000, 0x0000, 0x0001, 0x012A, 0x012B, 0x096B, 0x0A33, 0x3D7E, 0x1169, 0x0000, 0x0042,
    0x0085, 0x0002, 0x63F3, 0xCF1F, 0xCF3F, 0x7C74, 0x0004, 0xB63B, 0xEF9E, 0xDEFD, 0xE77F, 0xF7DF, 0x328F, 0xE77E, 0x19AA, 0x0002,
    0xADB9, 0x84B6, 0xA5B9, 0xCEBC, 0xB5DA, 0xBE5B, 0x6BD2, 0x9D58, 0xD6FD, 0xADB9, 0xBE5B, 0x8475, 0x6414, 0xEF9F, 0xB5FA, 0xBE1B,
    0xEF9F, 0x63F4, 0xF7BF, 0xE75E, 0xBE3A, 0x0907, 0x0084, 0x0045, 0xBE5B, 0x9558, 0x426D, 0x42AE, 0x42AD, 0x0886, 0x6BF3, 0xC67B,
    0xBE1A, 0xDF1D, 0xB63A, 0x1149, 0xE79F, 0xD6FD, 0xC6BC, 0xEFDF, 0x5392, 0x6C14, 0xDF3E, 0xADB9, 0xB61B, 0xE77F, 0x21CB, 0xBE9D,
    0x42AE, 0x0001, 0x0063, 0x0064, 0x0042, 0x0043, 0x0023, 0x0043, 0x0064, 0x0021, 0x0021, 0x0000, 0x0000, 0x0000, 0x0000, 0x0000,
    0x0000, 0x0000, 0x0000, 0x0000, 0x0000, 0x0000, 0x0000, 0x0000, 0x0000, 0x0000, 0x0000, 0x0000, 0x0000, 0x0000, 0x0064, 0x0022,
    0x096C, 0x014C, 0x0000, 0x0086, 0x0042, 0x0041, 0x0065, 0xA63D, 0x9DDB, 0x0044, 0x0907, 0xB6DE, 0x19CB, 0x0004, 0x094A, 0xCEFE,
    0x53B3, 0xC6BC, 0x0928, 0x0025, 0xADFA, 0x63D3, 0xCEDC, 0x9559, 0x63F6, 0x5BD4, 0x00EA, 0xC6BC, 0xA5BA, 0x63D5, 0x5BF5, 0x090B,
    0xA598, 0xB63C, 0x5BB5, 0x5BF5, 0xDF5F, 0x222D, 0xB65B, 0x5371, 0x0003, 0x00C6, 0x00A6, 0x0086, 0xB65C, 0xEFFF, 0xE7DF, 0xE7DF,
    0xE7FF, 0x2A2C, 0x2A0C, 0x74B7, 0x6C77, 0x959A, 0xA5DA, 0x4B51, 0xAE5C, 0x0045, 0x0003, 0x8559, 0x4B92, 0x8538, 0x855A, 0x4333,
    0x4BB4, 0xAE9E, 0x2A0C, 0x9E5E, 0x2A0B, 0x0002, 0x0042, 0x0042, 0x0063, 0x0022, 0x0A0F, 0x00A7, 0x0042, 0x0042, 0x0063, 0x0000,
    0x0000, 0x0000, 0x0000, 0x0000, 0x0000, 0x0000, 0x0000, 0x0000, 0x0000, 0x0000, 0x0000, 0x0000, 0x0000, 0x0000, 0x0000, 0x0000,
    0x0021, 0x0021, 0x00A8, 0x0043, 0x0043, 0x00C9, 0x00E8, 0x0000, 0x0042, 0x0064, 0x0002, 0x64B8, 0x4BB3, 0x0000, 0x1969, 0xA69E,
    0x198A, 0x0002, 0x1989, 0xAE7D, 0x4B92, 0xAE5C, 0x0086, 0x0025, 0xB67C, 0x3ACF, 0x328E, 0x9557, 0x8D17, 0xDF7F, 0x6436, 0x29ED,
    0x9557, 0x9517, 0xD73E, 0x7CF7, 0x8D99, 0xB63A, 0x84D7, 0x8D38, 0x6434, 0x00E8, 0xB67D, 0x3AAE, 0x0023, 0x00E7, 0x00A6, 0x00C7,
    0xAE9E, 0x4310, 0x10E7, 0x1169, 0x0928, 0x08E7, 0x9E5D, 0x8D58, 0x6C75, 0x95FA, 0x74F8, 0x4B92, 0x7D9C, 0x0023, 0x0023, 0x755B,
    0x3B10, 0x6CF9, 0x7539, 0x6476, 0x6CD7, 0x4B71, 0x1149, 0x7E1F, 0x1989, 0x0043, 0x0063, 0x0063, 0x0022, 0x016A, 0x13D7, 0x0064,
    0x0000, 0x0042, 0x0084, 0x0000, 0x0000, 0x0000, 0x0000, 0x0000, 0x0000, 0x0000, 0x0000, 0x0000, 0x0000, 0x0000, 0x0000, 0x0000,
    0x0000, 0x0000, 0x0000, 0x0000, 0x0000, 0x0023, 0x351D, 0x19AA, 0x0001, 0x0042, 0x022F, 0x00A5, 0x0001, 0x0085, 0x0043, 0x5D1C,
    0x3332, 0x0001, 0x08C6, 0x75DE, 0x7DDE, 0x753B, 0x863E, 0x759B, 0x226E, 0xA71F, 0x7D9B, 0x7DBB, 0xA77F, 0x2AD0, 0x6497, 0x64D9,
    0x5C98, 0x96BF, 0x4BD4, 0x6455, 0x6D59, 0x64D8, 0x96FE, 0x5416, 0x6D38, 0x8E7D, 0x64B8, 0x6D3A, 0x5435, 0x0929, 0x96DF, 0x220C,
    0x0044, 0x00E8, 0x0085, 0x116A, 0x9EDF, 0x19CB, 0x0001, 0x0043, 0x0002, 0x0907, 0x75FF, 0x5479, 0x4BB6, 0x655C, 0x5478, 0x222D,
    0x763F, 0x5CBA, 0x5499, 0x6E1F, 0x222D, 0x4C37, 0x54BA, 0x43B5, 0x4C17, 0x32D0, 0x118A, 0x65BF, 0x0927, 0x0064, 0x0063, 0x0042,
    0x0064, 0x02F1, 0x00A7, 0x0085, 0x0042, 0x0063, 0x0084, 0x0021, 0x0000, 0x0000, 0x0000, 0x0000, 0x0000, 0x0000, 0x0000, 0x0000,
    0x0000, 0x0000, 0x0000, 0x0000, 0x0000, 0x0000, 0x0000, 0x0000, 0x0020, 0x0000, 0x226E, 0x1A2F, 0x0001, 0x0022, 0x00C6, 0x0291,
    0x0002, 0x0043, 0x0042, 0x2311, 0x118A, 0x0022, 0x0022, 0x11CB, 0x43F5, 0x4416, 0x4436, 0x11CB, 0x0065, 0x3B52, 0x5497, 0x43F4,
    0x3372, 0x11EB, 0x5477, 0x5497, 0x5CB8, 0x4C15, 0x0949, 0x4C76, 0x54F8, 0x54F8, 0x54B6, 0x094A, 0x11AB, 0x54D7, 0x54F8, 0x5D38,
    0x4C34, 0x0929, 0x3C15, 0x0949, 0x00A6, 0x00E8, 0x00A6, 0x096A, 0x4416, 0x0927, 0x0064, 0x00A5, 0x00A6, 0x0084, 0x22AF, 0x3C17,
    0x3C17, 0x3C16, 0x1A8F, 0x0064, 0x2AF1, 0x3BB5, 0x2B53, 0x2354, 0x0107, 0x0948, 0x33B5, 0x33B5, 0x33F6, 0x22D0, 0x0927, 0x2353,
    0x0084, 0x0063, 0x0063, 0x0024, 0x0290, 0x0148, 0x09CF, 0x012B, 0x0085, 0x00E8, 0x010A, 0x0042, 0x0063, 0x0021, 0x0000, 0x0000,
    0x0000, 0x0000, 0x0000, 0x0000, 0x0000, 0x0000, 0x018D, 0x00E7, 0x0000, 0x0021, 0x0000, 0x0000, 0x0000, 0x0021, 0x0000, 0x00EA,
    0x010A, 0x0021, 0x0000, 0x01ED, 0x01CC, 0x0001, 0x0063, 0x0001, 0x0021, 0x0043, 0x0063, 0x0022, 0x0001, 0x0001, 0x0001, 0x0022,
    0x0064, 0x0002, 0x0002, 0x0002, 0x0003, 0x0044, 0x0002, 0x0003, 0x0003, 0x0024, 0x00C8, 0x0045, 0x0046, 0x0067, 0x0046, 0x00C9,
    0x00A8, 0x0046, 0x0047, 0x0048, 0x0067, 0x00C8, 0x0066, 0x00A7, 0x00E9, 0x0109, 0x00E9, 0x00C6, 0x0044, 0x0084, 0x00A5, 0x00A6,
    0x00A6, 0x00A6, 0x0043, 0x0002, 0x0003, 0x0003, 0x0023, 0x0064, 0x0002, 0x0002, 0x0002, 0x0002, 0x0063, 0x0022, 0x0001, 0x0001,
    0x0001, 0x0001, 0x0022, 0x0000, 0x0042, 0x0063, 0x0002, 0x22F3, 0x2BB4, 0x00E9, 0x012A, 0x0000, 0x0000, 0x0021, 0x0042, 0x0000,
    0x0000, 0x0021, 0x0021, 0x0000, 0x0000, 0x0000, 0x0000, 0x0000, 0x0021, 0x0000, 0x1270, 0x0A71, 0x0000, 0x0000, 0x0001, 0x0021,
    0x0001, 0x0001, 0x0042, 0x0022, 0x01AE, 0x00A6, 0x0022, 0x0045, 0x1B35, 0x0108, 0x0044, 0x0063, 0x0042, 0x0043, 0x0063, 0x0064,
    0x00A6, 0x00C7, 0x00E8, 0x014B, 0x016B, 0x016C, 0x09AD, 0x09AD, 0x09AC, 0x09AC, 0x018D, 0x09CE, 0x11EF, 0x1210, 0x1252, 0x1273,
    0x12B5, 0x1294, 0x1AB4, 0x1AF7, 0x1B17, 0x1AF7, 0x23DA, 0x2C7B, 0x23DA, 0x1AF6, 0x1293, 0x1272, 0x0A11, 0x012C, 0x012A, 0x00E9,
    0x00E7, 0x00A6, 0x00A7, 0x00C7, 0x00E9, 0x00E9, 0x010A, 0x016C, 0x1293, 0x1273, 0x01CF, 0x016D, 0x016C, 0x014B, 0x00E9, 0x00C8,
    0x00A6, 0x0085, 0x0085, 0x0085, 0x0044, 0x0043, 0x0042, 0x0022, 0x0043, 0x0022, 0x0001, 0x118C, 0x1233, 0x014B, 0x0000, 0x0022,
    0x0000, 0x0022, 0x0063, 0x0000, 0x0000, 0x0000, 0x0021, 0x0000, 0x0000, 0x0000, 0x0000, 0x0000, 0x0021, 0x0042, 0x0000, 0x0084,
    0x0108, 0x0000, 0x0021, 0x0022, 0x0021, 0x0000, 0x0084, 0x0021, 0x0084, 0x01AE, 0x0023, 0x0065, 0x11CD, 0x2B98, 0x0087, 0x0085,
    0x0064, 0x0085, 0x00A6, 0x00C7, 0x010A, 0x012B, 0x018E, 0x0273, 0x0273, 0x0272, 0x0A93, 0x12B3, 0x1AB3, 0x1B15, 0x0C1A, 0x0C1A,
    0x23FA, 0x243B, 0x349E, 0x45BF, 0x4DDF, 0x453F, 0x345D, 0x343D, 0x349E, 0x347E, 0x457F, 0x66FF, 0x45FF, 0x34DF, 0x2BFB, 0x23BA,
    0x1BDB, 0x0A31, 0x010B, 0x012B, 0x0109, 0x014C, 0x098D, 0x098D, 0x01AF, 0x01AF, 0x016E, 0x0254, 0x34FE, 0x249D, 0x02D5, 0x0252,
    0x0211, 0x01CF, 0x0A33, 0x01D2, 0x01B0, 0x018F, 0x016E, 0x01AF, 0x0A51, 0x010C, 0x012B, 0x014B, 0x016B, 0x018B, 0x018A, 0x0210,
    0x0B59, 0x0064, 0x1106, 0x0884, 0x0000, 0x0042, 0x00A6, 0x0000, 0x0000, 0x0000, 0x0000, 0x0000, 0x0000, 0x0000, 0x0000, 0x0000,
    0x0000, 0x0021, 0x0021, 0x0000, 0x00C7, 0x00C6, 0x0000, 0x0021, 0x0000, 0x0000, 0x0063, 0x0042, 0x0000, 0x014A, 0x0149, 0x0000,
    0x0001, 0x1A2F, 0x11CD, 0x0002, 0x00A5, 0x00A7, 0x00E8, 0x00E8, 0x00C8, 0x0085, 0x0085, 0x0086, 0x00A6, 0x00A7, 0x00A7, 0x00A7,
    0x00A8, 0x00E9, 0x0250, 0x0271, 0x0251, 0x0271, 0x02F4, 0x1BB9, 0x1B99, 0x12F6, 0x01B0, 0x01D2, 0x0214, 0x016F, 0x0191, 0x0235,
    0x0235, 0x01B1, 0x014E, 0x012C, 0x012C, 0x1B14, 0x014B, 0x00C7, 0x00C9, 0x22B4, 0x43F9, 0x4C5B, 0x1398, 0x0253, 0x00A6, 0x00A7,
    0x00CA, 0x00CA, 0x00A8, 0x0086, 0x0086, 0x0066, 0x018C, 0x016D, 0x012C, 0x012B, 0x00E9, 0x012A, 0x0A30, 0x0AB4, 0x010B, 0x014B,
    0x014A, 0x01AC, 0x018B, 0x0272, 0x018D, 0x0000, 0x0884, 0x0042, 0x0000, 0x0063, 0x00E7, 0x0000, 0x0000, 0x0000, 0x0021, 0x0000,
    0x0000, 0x0000, 0x0000, 0x0000, 0x0000, 0x0000, 0x0042, 0x0000, 0x0000, 0x014B, 0x0042, 0x0000, 0x0001, 0x0000, 0x0022, 0x0042,
    0x0042, 0x0021, 0x01AD, 0x00A5, 0x0022, 0x0044, 0x1336, 0x01D0, 0x0066, 0x0043, 0x0043, 0x0043, 0x0065, 0x0064, 0x0063, 0x0085,
    0x00A5, 0x00A5, 0x00A5, 0x00A6, 0x00A6, 0x00A5, 0x0086, 0x00A6, 0x00A6, 0x00A7, 0x010A, 0x00C9, 0x00EA, 0x00C8, 0x00E9, 0x010A,
    0x012A, 0x0109, 0x012A, 0x010A, 0x0109, 0x0109, 0x0109, 0x0108, 0x00C7, 0x094B, 0x2B55, 0x0109, 0x012A, 0x01CF, 0x00A8, 0x010A,
    0x01AF, 0x00A7, 0x00A6, 0x00A7, 0x00A6, 0x00A6, 0x00A7, 0x0086, 0x09CF, 0x1B38, 0x0087, 0x0064, 0x0065, 0x00A6, 0x00C7, 0x0042,
    0x0002, 0x01CB, 0x018B, 0x0001, 0x0021, 0x0001, 0x0000, 0x0087, 0x00C9, 0x0000, 0x0001, 0x0021, 0x0000, 0x0042, 0x00A5, 0x0000,
    0x0000, 0x0021, 0x0000, 0x0000, 0x0000, 0x0000, 0x0000, 0x0000, 0x0000, 0x0000, 0x0021, 0x0063, 0x0000, 0x0063, 0x01AC, 0x0000,
    0x0021, 0x0000, 0x0042, 0x0042, 0x0021, 0x0000, 0x0064, 0x020F, 0x022E, 0x02D0, 0x2438, 0x6DFF, 0x02D2, 0x028D, 0x024C, 0x022B,
    0x01EB, 0x01AB, 0x01F0, 0x0085, 0x0084, 0x0085, 0x00A5, 0x00A6, 0x0084, 0x0084, 0x0084, 0x0084, 0x0084, 0x00A5, 0x00E7, 0x00A5,
    0x00A5, 0x00A5, 0x00C7, 0x00A6, 0x00A6, 0x00C6, 0x00C7, 0x00C7, 0x00A6, 0x00A6, 0x00C6, 0x00A6, 0x00C7, 0x0065, 0x1292, 0x01AE,
    0x00C7, 0x0108, 0x0084, 0x0063, 0x014B, 0x012B, 0x00E8, 0x012B, 0x010A, 0x00E9, 0x00C7, 0x00A9, 0x2BBA, 0x86BF, 0x0170, 0x010A,
    0x014C, 0x00C8, 0x0109, 0x00E9, 0x0064, 0x0043, 0x028F, 0x0109, 0x0022, 0x0042, 0x0021, 0x00E9, 0x00E8, 0x0000, 0x0021, 0x0021,
    0x0000, 0x0021, 0x0063, 0x0000, 0x0021, 0x0021, 0x0000, 0x0000, 0x0000, 0x0000, 0x0000, 0x0000, 0x0000, 0x0000, 0x0000, 0x0042,
    0x0063, 0x0021, 0x016A, 0x0128, 0x0000, 0x0000, 0x0063, 0x0042, 0x0000, 0x0021, 0x0021, 0x0022, 0x0064, 0x00C6, 0x00EA, 0x018F,
    0x0109, 0x00C6, 0x00A5, 0x00A5, 0x0063, 0x0084, 0x012A, 0x0063, 0x0063, 0x0063, 0x0084, 0x0084, 0x0063, 0x0063, 0x0085, 0x00A5,
    0x0064, 0x0064, 0x0063, 0x0063, 0x00E7, 0x00C6, 0x0042, 0x00E7, 0x018D, 0x0064, 0x0085, 0x0085, 0x0084, 0x0084, 0x0085, 0x0084,
    0x0085, 0x00A6, 0x00C8, 0x010A, 0x00C7, 0x0043, 0x0086, 0x0064, 0x00C7, 0x00E9, 0x00C7, 0x00C8, 0x00EA, 0x00E9, 0x00E8, 0x014D,
    0x0255, 0x09F0, 0x010A, 0x0064, 0x0085, 0x0042, 0x0001, 0x00E9, 0x0063, 0x0085, 0x0108, 0x1356, 0x00C8, 0x0021, 0x0022, 0x0085,
    0x0085, 0x0000, 0x0021, 0x0021, 0x0000, 0x0042, 0x00A5, 0x0021, 0x0021, 0x0000, 0x0000, 0x0000, 0x0000, 0x0000, 0x0000, 0x0000,
    0x0000, 0x0000, 0x0000, 0x0000, 0x0000, 0x0000, 0x0000, 0x01EE, 0x00E7, 0x0000, 0x0063, 0x0042, 0x0021, 0x0021, 0x0000, 0x0001,
    0x0021, 0x0063, 0x0064, 0x0064, 0x0064, 0x0042, 0x0021, 0x0021, 0x00A6, 0x0043, 0x0000, 0x0021, 0x0022, 0x0021, 0x0042, 0x0042,
    0x0021, 0x0043, 0x00A6, 0x00A5, 0x0063, 0x0063, 0x0063, 0x0043, 0x0085, 0x0085, 0x0042, 0x0085, 0x014A, 0x0042, 0x0063, 0x0063,
    0x0043, 0x0064, 0x0063, 0x0042, 0x0043, 0x0043, 0x0085, 0x0064, 0x00A7, 0x0064, 0x00A6, 0x0064, 0x0022, 0x0022, 0x0043, 0x0064,
    0x0064, 0x0064, 0x0043, 0x0042, 0x010A, 0x00A8, 0x0064, 0x0085, 0x0064, 0x0064, 0x0042, 0x0021, 0x00A7, 0x0109, 0x0065, 0x12D6,
    0x018D, 0x0001, 0x0021, 0x0064, 0x0084, 0x0000, 0x0000, 0x0021, 0x0000, 0x0000, 0x0042, 0x0042, 0x0000, 0x0000, 0x0000, 0x0000,
    0x0000, 0x0000, 0x0000, 0x0000, 0x0000, 0x0000, 0x0000, 0x0000, 0x0000, 0x0021, 0x0000, 0x0085, 0x1B77, 0x0022, 0x0083, 0x0063,
    0x0021, 0x0000, 0x0021, 0x0000, 0x0022, 0x0043, 0x0042, 0x0042, 0x0021, 0x0021, 0x0000, 0x0043, 0x0063, 0x0021, 0x0021, 0x0021,
    0x0021, 0x0021, 0x0042, 0x0043, 0x0021, 0x0042, 0x0084, 0x0042, 0x0042, 0x0084, 0x0085, 0x0042, 0x0084, 0x00A5, 0x0064, 0x00A5,
    0x014A, 0x0022, 0x0042, 0x0042, 0x0063, 0x0063, 0x0043, 0x0021, 0x0042, 0x0042, 0x00C6, 0x0022, 0x0042, 0x0064, 0x0043, 0x0043,
    0x0064, 0x0084, 0x0064, 0x0084, 0x00A6, 0x0085, 0x00C7, 0x0064, 0x0043, 0x00A6, 0x0042, 0x0022, 0x0042, 0x0000, 0x0021, 0x0000,
    0x0043, 0x00C8, 0x0042, 0x00C8, 0x0064, 0x0001, 0x0000, 0x0042, 0x0043, 0x0000, 0x0021, 0x0021, 0x0021, 0x0021, 0x0063, 0x0021,
    0x0000, 0x0000, 0x0000, 0x0000, 0x0000, 0x0000, 0x0000, 0x0000, 0x0000, 0x0000, 0x0000, 0x0000, 0x0000, 0x0000, 0x0020, 0x0021,
    0x0064, 0x0021, 0x0062, 0x0042, 0x0021, 0x0000, 0x0000, 0x0000, 0x0021, 0x0000, 0x0084, 0x00C6, 0x00A5, 0x0085, 0x0085, 0x0063,
    0x0021, 0x0042, 0x0021, 0x0021, 0x0021, 0x0021, 0x0042, 0x0063, 0x0021, 0x0063, 0x0084, 0x0021, 0x0021, 0x0042, 0x0042, 0x0021,
    0x0085, 0x00C6, 0x0063, 0x00A6, 0x014A, 0x0021, 0x0042, 0x0042, 0x0043, 0x0042, 0x0021, 0x0021, 0x0021, 0x0022, 0x0085, 0x0042,
    0x0021, 0x0021, 0x0021, 0x0042, 0x0021, 0x0021, 0x0000, 0x0022, 0x0042, 0x0021, 0x0022, 0x00C6, 0x0042, 0x0021, 0x00A6, 0x0021,
    0x0020, 0x0021, 0x0000, 0x0021, 0x0000, 0x00A6, 0x0085, 0x0063, 0x0042, 0x0000, 0x0000, 0x0000, 0x0021, 0x0042, 0x0042, 0x00A5,
    0x0063, 0x0084, 0x0084, 0x0000, 0x0000, 0x0000, 0x0000, 0x0000, 0x0000, 0x0000, 0x0000, 0x0000, 0x0000, 0x0000, 0x0000, 0x0000,
    0x0000, 0x0000, 0x0000, 0x0021, 0x0000, 0x0020, 0x0063, 0x0084, 0x0042, 0x0000, 0x0000, 0x0000, 0x0000, 0x0042, 0x00C6, 0x0021,
    0x0042, 0x0042, 0x0022, 0x0021, 0x0021, 0x0021, 0x0021, 0x0021, 0x0021, 0x0021, 0x0021, 0x0042, 0x0021, 0x00A5, 0x00E8, 0x0021,
    0x0042, 0x0085, 0x0084, 0x0021, 0x0084, 0x0084, 0x0021, 0x0084, 0x0129, 0x0021, 0x0042, 0x0042, 0x0022, 0x0021, 0x0021, 0x0042,
    0x0042, 0x0042, 0x0084, 0x0043, 0x0063, 0x0084, 0x0042, 0x0021, 0x0042, 0x0084, 0x0063, 0x0109, 0x0042, 0x0000, 0x0021, 0x0021,
    0x0064, 0x0000, 0x0063, 0x0064, 0x0000, 0x0021, 0x0000, 0x0000, 0x0000, 0x0063, 0x00A6, 0x0022, 0x0021, 0x0000, 0x0000, 0x0000,
    0x0021, 0x0000, 0x0042, 0x0063, 0x0000, 0x0000, 0x0000, 0x0000, 0x0000, 0x0000, 0x0000, 0x0000, 0x0000, 0x0000, 0x0000, 0x0000,
    0x0000, 0x0000, 0x0000, 0x0000, 0x0000, 0x0000, 0x0000, 0x0021, 0x0021, 0x0021, 0x0063, 0x0084, 0x0042, 0x0000, 0x0000, 0x0000,
    0x0021, 0x0063, 0x0042, 0x0021, 0x0041, 0x0042, 0x0021, 0x0021, 0x0000, 0x0021, 0x0021, 0x0021, 0x0021, 0x0021, 0x0042, 0x0042,
    0x0000, 0x00E7, 0x00E7, 0x0000, 0x0042, 0x00C6, 0x00A6, 0x0042, 0x0063, 0x0084, 0x0021, 0x0084, 0x0108, 0x0042, 0x0021, 0x0021,
    0x0021, 0x0021, 0x0021, 0x0042, 0x0042, 0x0021, 0x0084, 0x0042, 0x0021, 0x0083, 0x0021, 0x0000, 0x0021, 0x0021, 0x0020, 0x0042,
    0x0021, 0x0000, 0x0000, 0x0000, 0x0042, 0x0042, 0x0000, 0x0084, 0x0042, 0x0042, 0x0021, 0x0000, 0x0000, 0x0042, 0x0042, 0x0042,
    0x0000, 0x0000, 0x0000, 0x0000, 0x0000, 0x0000, 0x0042, 0x0021, 0x0000, 0x0000, 0x0000, 0x0000, 0x0000, 0x0000, 0x0000, 0x0000,
    0x0000, 0x0000, 0x0000, 0x0000, 0x0000, 0x0000, 0x0000, 0x0000, 0x0000, 0x0000, 0x0000, 0x0021, 0x0021, 0x0000, 0x0042, 0x0063,
    0x0021, 0x0000, 0x0000, 0x0021, 0x0021, 0x0021, 0x0021, 0x0021, 0x0021, 0x0021, 0x0021, 0x0021, 0x0000, 0x0021, 0x0021, 0x0042,
    0x0021, 0x0021, 0x0021, 0x0063, 0x0000, 0x00C6, 0x00C7, 0x0000, 0x0021, 0x0042, 0x0063, 0x0042, 0x0021, 0x0021, 0x0000, 0x0042,
    0x00A6, 0x0042, 0x0021, 0x0021, 0x0021, 0x0021, 0x0021, 0x0043, 0x0042, 0x0021, 0x00A5, 0x0042, 0x0021, 0x0062, 0x0021, 0x0021,
    0x0000, 0x0021, 0x0021, 0x0020, 0x0000, 0x0000, 0x0000, 0x0000, 0x0000, 0x0063, 0x0043, 0x0021, 0x00A5, 0x0042, 0x0021, 0x0000,
    0x0000, 0x0042, 0x0020, 0x0063, 0x0000, 0x0000, 0x0000, 0x0021, 0x0000, 0x0042, 0x0021, 0x0020, 0x0000, 0x0000, 0x0021, 0x0000,
    0x0000, 0x0000, 0x0000, 0x0000, 0x0000, 0x0000, 0x0000, 0x0000, 0x0000, 0x0000, 0x0000, 0x0000, 0x0000, 0x0000, 0x0000, 0x0021,
    0x0000, 0x0000, 0x0042, 0x0042, 0x0000, 0x0000, 0x0021, 0x0021, 0x0021, 0x0084, 0x0021, 0x0021, 0x0021, 0x0000, 0x0000, 0x0000,
    0x0000, 0x0000, 0x0021, 0x0021, 0x0021, 0x0021, 0x0021, 0x0063, 0x0000, 0x00C6, 0x012A, 0x0000, 0x0021, 0x0021, 0x0063, 0x0021,
    0x0063, 0x0064, 0x0000, 0x0042, 0x00A5, 0x0021, 0x0000, 0x0000, 0x0000, 0x0000, 0x0000, 0x0021, 0x0042, 0x0021, 0x0084, 0x0042,
    0x0021, 0x0083, 0x0041, 0x0021, 0x0021, 0x0042, 0x0021, 0x0021, 0x0021, 0x0021, 0x0000, 0x0020, 0x0000, 0x0021, 0x0063, 0x0021,
    0x0063, 0x0084, 0x0000, 0x0000, 0x0000, 0x0063, 0x0021, 0x0021, 0x0000, 0x0000, 0x0000, 0x0000, 0x0042, 0x0042, 0x0000, 0x0021,
    0x0000, 0x0000, 0x0021, 0x0000, 0x0000, 0x0000, 0x0000, 0x0000, 0x0000, 0x0000, 0x0000, 0x0000, 0x0000, 0x0000, 0x0000, 0x0000,
    0x0000, 0x0000, 0x0000, 0x0000, 0x0000, 0x0000, 0x0020, 0x0021, 0x0021, 0x0020, 0x0000, 0x0000, 0x0021, 0x0063, 0x0021, 0x0021,
    0x0020, 0x0000, 0x0000, 0x0000, 0x0000, 0x0000, 0x0021, 0x0000, 0x0021, 0x0021, 0x0021, 0x0063, 0x0000, 0x00A5, 0x0108, 0x0000,
    0x0021, 0x0021, 0x0021, 0x0000, 0x00A5, 0x00C6, 0x0000, 0x0063, 0x0109, 0x0000, 0x0021, 0x0000, 0x0000, 0x0000, 0x0000, 0x0021,
    0x0042, 0x0021, 0x0063, 0x0021, 0x0000, 0x0063, 0x0021, 0x0021, 0x0021, 0x0021, 0x0021, 0x0021, 0x0021, 0x0021, 0x0000, 0x0000,
    0x0000, 0x0042, 0x0042, 0x0020, 0x0021, 0x0063, 0x0021, 0x0000, 0x0000, 0x0084, 0x0021, 0x0042, 0x0000, 0x0000, 0x0000, 0x0021,
    0x0063, 0x0000, 0x0000, 0x0000, 0x0000, 0x0000, 0x0021, 0x0000, 0x0000, 0x0000, 0x0000, 0x0000, 0x0000, 0x0000, 0x0000, 0x0000,
    0x0000, 0x0000, 0x0000, 0x0000, 0x0000, 0x0000, 0x0000, 0x0000, 0x0000, 0x0000, 0x0020, 0x0000, 0x0000, 0x0021, 0x0021, 0x0000,
    0x0000, 0x0042, 0x0000, 0x0000, 0x0000, 0x0000, 0x0000, 0x0000, 0x0000, 0x0021, 0x0021, 0x0000, 0x0000, 0x0000, 0x0021, 0x0084,
    0x0000, 0x0063, 0x00A5, 0x0000, 0x0000, 0x0000, 0x0000, 0x0000, 0x0000, 0x0000, 0x0000, 0x0000, 0x0042, 0x0021, 0x0000, 0x0000,
    0x0000, 0x0000, 0x0000, 0x0021, 0x0021, 0x0000, 0x0063, 0x0021, 0x0000, 0x0042, 0x0021, 0x0042, 0x0000, 0x0021, 0x0021, 0x0021,
    0x0021, 0x0021, 0x0000, 0x0021, 0x0021, 0x0083, 0x0042, 0x0000, 0x0000, 0x0021, 0x0042, 0x0000, 0x0000, 0x00A6, 0x0042, 0x0042,
    0x0000, 0x0000, 0x0000, 0x0021, 0x0021, 0x0000, 0x0000, 0x0000, 0x0000, 0x0000, 0x0021, 0x0000, 0x0000, 0x0000, 0x0000, 0x0000
}; */
/* USER CODE END PM */

CRC_HandleTypeDef hcrc;

DMA2D_HandleTypeDef hdma2d;

I2C_HandleTypeDef hi2c3;

LTDC_HandleTypeDef hltdc;

SPI_HandleTypeDef hspi5;

UART_HandleTypeDef huart1;

SDRAM_HandleTypeDef hsdram1;

void SystemClock_Config(void);
static void MX_GPIO_Init(void);
static void MX_USART1_UART_Init(void);
static void MX_CRC_Init(void);
static void MX_DMA2D_Init(void);
static void MX_FMC_Init(void);
static void MX_I2C3_Init(void);
static void MX_LTDC_Init(void);
static void MX_SPI5_Init(void);
/* USER CODE BEGIN PFP */
static void goto_application(void);
/* USER CODE END PFP */

int main(void)
{

  /* MCU Configuration--------------------------------------------------------*/

  /* Reset of all peripherals, Initializes the Flash interface and the Systick. */
  HAL_Init();

  /* Configure the system clock */
  SystemClock_Config();

  /* Initialize all configured peripherals */
  MX_GPIO_Init();
  MX_USART1_UART_Init();
  MX_CRC_Init();
  MX_DMA2D_Init();
  MX_FMC_Init();
  MX_I2C3_Init();
  MX_LTDC_Init();
  MX_SPI5_Init();
  /* USER CODE BEGIN 2 */

   /*uint16_t *fb = (uint16_t*)LCD_FRAME_BUFFER;
   for(uint32_t i = 0; i < 240 * 320; i++)
   {
       fb[i] = image_data[i];
   } */
  const char* BOOTLOADER_BANNER =
        "   ______     _____     _____   _______            _____       _____     ____     ______   ______    \r\n"
        " ||______]| ||     || ||     ||    ||    ||      ||     ||   ||_____|| ||    \\ ||______  ||____//   \r\n"
        " ||______]| ||_____|| ||_____||    ||    ||_____ ||_____||   ||     || ||____// ||______  ||    \\\\ \r\n"
        "                                                                                                     \r\n"
        "          					                                    by Fadel_Youssef\r\n";

  printf("%s\r\n", BOOTLOADER_BANNER);
  printf("Starting Bootloader...\r\n");
  HAL_GPIO_WritePin (GPIOG, GPIO_PIN_13, GPIO_PIN_SET); //LED ON
  HAL_Delay(2000); //2 Seconds delay

  /* USER CODE END 2 */

  /* Infinite loop */
  while (1)
  {

    /* USER CODE BEGIN 3 */

	 if(HAL_GPIO_ReadPin(GPIOA, GPIO_PIN_0))
	 {
	 	  printf("Failed to start the application!\r\n");
	 }

	 while(HAL_GPIO_ReadPin(GPIOA, GPIO_PIN_0))
	 {
	  	 HAL_GPIO_WritePin(GPIOG, GPIO_PIN_13, GPIO_PIN_RESET); //LED ON
	  	 HAL_Delay(1000);
	     HAL_GPIO_WritePin(GPIOG, GPIO_PIN_13, GPIO_PIN_SET); //LED ON
	     HAL_Delay(1000);
	 }

	 goto_application();

  }
  /* USER CODE END 3 */
}

void SystemClock_Config(void)
{
  RCC_OscInitTypeDef RCC_OscInitStruct = {0};
  RCC_ClkInitTypeDef RCC_ClkInitStruct = {0};

  /** Configure the main internal regulator output voltage
  */
  __HAL_RCC_PWR_CLK_ENABLE();
  __HAL_PWR_VOLTAGESCALING_CONFIG(PWR_REGULATOR_VOLTAGE_SCALE1);

  /** Initializes the RCC Oscillators according to the specified parameters
  * in the RCC_OscInitTypeDef structure.
  */
  RCC_OscInitStruct.OscillatorType = RCC_OSCILLATORTYPE_HSI;
  RCC_OscInitStruct.HSIState = RCC_HSI_ON;
  RCC_OscInitStruct.HSICalibrationValue = RCC_HSICALIBRATION_DEFAULT;
  RCC_OscInitStruct.PLL.PLLState = RCC_PLL_ON;
  RCC_OscInitStruct.PLL.PLLSource = RCC_PLLSOURCE_HSI;
  RCC_OscInitStruct.PLL.PLLM = 8;
  RCC_OscInitStruct.PLL.PLLN = 180;
  RCC_OscInitStruct.PLL.PLLP = RCC_PLLP_DIV2;
  RCC_OscInitStruct.PLL.PLLQ = 3;
  if (HAL_RCC_OscConfig(&RCC_OscInitStruct) != HAL_OK)
  {
    Error_Handler();
  }

  /** Activate the Over-Drive mode
  */
  if (HAL_PWREx_EnableOverDrive() != HAL_OK)
  {
    Error_Handler();
  }

  /** Initializes the CPU, AHB and APB buses clocks
  */
  RCC_ClkInitStruct.ClockType = RCC_CLOCKTYPE_HCLK|RCC_CLOCKTYPE_SYSCLK
                              |RCC_CLOCKTYPE_PCLK1|RCC_CLOCKTYPE_PCLK2;
  RCC_ClkInitStruct.SYSCLKSource = RCC_SYSCLKSOURCE_PLLCLK;
  RCC_ClkInitStruct.AHBCLKDivider = RCC_SYSCLK_DIV1;
  RCC_ClkInitStruct.APB1CLKDivider = RCC_HCLK_DIV4;
  RCC_ClkInitStruct.APB2CLKDivider = RCC_HCLK_DIV2;

  if (HAL_RCC_ClockConfig(&RCC_ClkInitStruct, FLASH_LATENCY_5) != HAL_OK)
  {
    Error_Handler();
  }
}

static void MX_CRC_Init(void)
{

  hcrc.Instance = CRC;
  if (HAL_CRC_Init(&hcrc) != HAL_OK)
  {
    Error_Handler();
  }

}

static void MX_DMA2D_Init(void)
{

  hdma2d.Instance = DMA2D;
  hdma2d.Init.Mode = DMA2D_M2M;
  hdma2d.Init.ColorMode = DMA2D_OUTPUT_ARGB8888;
  hdma2d.Init.OutputOffset = 0;
  hdma2d.LayerCfg[1].InputOffset = 0;
  hdma2d.LayerCfg[1].InputColorMode = DMA2D_INPUT_ARGB8888;
  hdma2d.LayerCfg[1].AlphaMode = DMA2D_NO_MODIF_ALPHA;
  hdma2d.LayerCfg[1].InputAlpha = 0;
  if (HAL_DMA2D_Init(&hdma2d) != HAL_OK)
  {
    Error_Handler();
  }
  if (HAL_DMA2D_ConfigLayer(&hdma2d, 1) != HAL_OK)
  {
    Error_Handler();
  }

}

static void MX_I2C3_Init(void)
{

  hi2c3.Instance = I2C3;
  hi2c3.Init.ClockSpeed = 100000;
  hi2c3.Init.DutyCycle = I2C_DUTYCYCLE_2;
  hi2c3.Init.OwnAddress1 = 0;
  hi2c3.Init.AddressingMode = I2C_ADDRESSINGMODE_7BIT;
  hi2c3.Init.DualAddressMode = I2C_DUALADDRESS_DISABLE;
  hi2c3.Init.OwnAddress2 = 0;
  hi2c3.Init.GeneralCallMode = I2C_GENERALCALL_DISABLE;
  hi2c3.Init.NoStretchMode = I2C_NOSTRETCH_DISABLE;
  if (HAL_I2C_Init(&hi2c3) != HAL_OK)
  {
    Error_Handler();
  }

  /** Configure Analogue filter
  */
  if (HAL_I2CEx_ConfigAnalogFilter(&hi2c3, I2C_ANALOGFILTER_ENABLE) != HAL_OK)
  {
    Error_Handler();
  }

  /** Configure Digital filter
  */
  if (HAL_I2CEx_ConfigDigitalFilter(&hi2c3, 0) != HAL_OK)
  {
    Error_Handler();
  }

}

static void MX_LTDC_Init(void)
{

  LTDC_LayerCfgTypeDef pLayerCfg = {0};
  LTDC_LayerCfgTypeDef pLayerCfg1 = {0};

  hltdc.Instance = LTDC;
  hltdc.Init.HSPolarity = LTDC_HSPOLARITY_AL;
  hltdc.Init.VSPolarity = LTDC_VSPOLARITY_AL;
  hltdc.Init.DEPolarity = LTDC_DEPOLARITY_AL;
  hltdc.Init.PCPolarity = LTDC_PCPOLARITY_IPC;
  hltdc.Init.HorizontalSync = 7;
  hltdc.Init.VerticalSync = 3;
  hltdc.Init.AccumulatedHBP = 14;
  hltdc.Init.AccumulatedVBP = 5;
  hltdc.Init.AccumulatedActiveW = 654;
  hltdc.Init.AccumulatedActiveH = 485;
  hltdc.Init.TotalWidth = 660;
  hltdc.Init.TotalHeigh = 487;
  hltdc.Init.Backcolor.Blue = 0;
  hltdc.Init.Backcolor.Green = 0;
  hltdc.Init.Backcolor.Red = 0;
  if (HAL_LTDC_Init(&hltdc) != HAL_OK)
  {
    Error_Handler();
  }
  pLayerCfg.WindowX0 = 0;
  pLayerCfg.WindowX1 = 0;
  pLayerCfg.WindowY0 = 0;
  pLayerCfg.WindowY1 = 0;
  pLayerCfg.PixelFormat = LTDC_PIXEL_FORMAT_ARGB8888;
  pLayerCfg.Alpha = 0;
  pLayerCfg.Alpha0 = 0;
  pLayerCfg.BlendingFactor1 = LTDC_BLENDING_FACTOR1_CA;
  pLayerCfg.BlendingFactor2 = LTDC_BLENDING_FACTOR2_CA;
  pLayerCfg.FBStartAdress = 0;
  pLayerCfg.ImageWidth = 0;
  pLayerCfg.ImageHeight = 0;
  pLayerCfg.Backcolor.Blue = 0;
  pLayerCfg.Backcolor.Green = 0;
  pLayerCfg.Backcolor.Red = 0;
  if (HAL_LTDC_ConfigLayer(&hltdc, &pLayerCfg, 0) != HAL_OK)
  {
    Error_Handler();
  }
  pLayerCfg1.WindowX0 = 0;
  pLayerCfg1.WindowX1 = 0;
  pLayerCfg1.WindowY0 = 0;
  pLayerCfg1.WindowY1 = 0;
  pLayerCfg1.PixelFormat = LTDC_PIXEL_FORMAT_ARGB8888;
  pLayerCfg1.Alpha = 0;
  pLayerCfg1.Alpha0 = 0;
  pLayerCfg1.BlendingFactor1 = LTDC_BLENDING_FACTOR1_CA;
  pLayerCfg1.BlendingFactor2 = LTDC_BLENDING_FACTOR2_CA;
  pLayerCfg1.FBStartAdress = 0;
  pLayerCfg1.ImageWidth = 0;
  pLayerCfg1.ImageHeight = 0;
  pLayerCfg1.Backcolor.Blue = 0;
  pLayerCfg1.Backcolor.Green = 0;
  pLayerCfg1.Backcolor.Red = 0;
  if (HAL_LTDC_ConfigLayer(&hltdc, &pLayerCfg1, 1) != HAL_OK)
  {
    Error_Handler();
  }

}

static void MX_SPI5_Init(void)
{

  /* SPI5 parameter configuration*/
  hspi5.Instance = SPI5;
  hspi5.Init.Mode = SPI_MODE_MASTER;
  hspi5.Init.Direction = SPI_DIRECTION_2LINES;
  hspi5.Init.DataSize = SPI_DATASIZE_8BIT;
  hspi5.Init.CLKPolarity = SPI_POLARITY_LOW;
  hspi5.Init.CLKPhase = SPI_PHASE_1EDGE;
  hspi5.Init.NSS = SPI_NSS_SOFT;
  hspi5.Init.BaudRatePrescaler = SPI_BAUDRATEPRESCALER_2;
  hspi5.Init.FirstBit = SPI_FIRSTBIT_MSB;
  hspi5.Init.TIMode = SPI_TIMODE_DISABLE;
  hspi5.Init.CRCCalculation = SPI_CRCCALCULATION_DISABLE;
  hspi5.Init.CRCPolynomial = 10;
  if (HAL_SPI_Init(&hspi5) != HAL_OK)
  {
    Error_Handler();
  }

}

static void MX_USART1_UART_Init(void)
{

  huart1.Instance = USART1;
  huart1.Init.BaudRate = 115200;
  huart1.Init.WordLength = UART_WORDLENGTH_8B;
  huart1.Init.StopBits = UART_STOPBITS_1;
  huart1.Init.Parity = UART_PARITY_NONE;
  huart1.Init.Mode = UART_MODE_TX_RX;
  huart1.Init.HwFlowCtl = UART_HWCONTROL_NONE;
  huart1.Init.OverSampling = UART_OVERSAMPLING_16;
  if (HAL_UART_Init(&huart1) != HAL_OK)
  {
    Error_Handler();
  }

}

/* FMC initialization function */
static void MX_FMC_Init(void)
{

  FMC_SDRAM_TimingTypeDef SdramTiming = {0};

  /** Perform the SDRAM1 memory initialization sequence
  */
  hsdram1.Instance = FMC_SDRAM_DEVICE;
  /* hsdram1.Init */
  hsdram1.Init.SDBank = FMC_SDRAM_BANK2;
  hsdram1.Init.ColumnBitsNumber = FMC_SDRAM_COLUMN_BITS_NUM_8;
  hsdram1.Init.RowBitsNumber = FMC_SDRAM_ROW_BITS_NUM_12;
  hsdram1.Init.MemoryDataWidth = FMC_SDRAM_MEM_BUS_WIDTH_16;
  hsdram1.Init.InternalBankNumber = FMC_SDRAM_INTERN_BANKS_NUM_4;
  hsdram1.Init.CASLatency = FMC_SDRAM_CAS_LATENCY_1;
  hsdram1.Init.WriteProtection = FMC_SDRAM_WRITE_PROTECTION_DISABLE;
  hsdram1.Init.SDClockPeriod = FMC_SDRAM_CLOCK_DISABLE;
  hsdram1.Init.ReadBurst = FMC_SDRAM_RBURST_DISABLE;
  hsdram1.Init.ReadPipeDelay = FMC_SDRAM_RPIPE_DELAY_0;
  /* SdramTiming */
  SdramTiming.LoadToActiveDelay = 16;
  SdramTiming.ExitSelfRefreshDelay = 16;
  SdramTiming.SelfRefreshTime = 16;
  SdramTiming.RowCycleDelay = 16;
  SdramTiming.WriteRecoveryTime = 16;
  SdramTiming.RPDelay = 16;
  SdramTiming.RCDDelay = 16;

  if (HAL_SDRAM_Init(&hsdram1, &SdramTiming) != HAL_OK)
  {
    Error_Handler( );
  }

}

static void MX_GPIO_Init(void)
{
  GPIO_InitTypeDef GPIO_InitStruct = {0};

  /* GPIO Ports Clock Enable */
  __HAL_RCC_GPIOF_CLK_ENABLE();
  __HAL_RCC_GPIOC_CLK_ENABLE();
  __HAL_RCC_GPIOA_CLK_ENABLE();
  __HAL_RCC_GPIOB_CLK_ENABLE();
  __HAL_RCC_GPIOG_CLK_ENABLE();
  __HAL_RCC_GPIOE_CLK_ENABLE();
  __HAL_RCC_GPIOD_CLK_ENABLE();

  /*Configure GPIO pin Output Level */
  HAL_GPIO_WritePin(GPIOG, GPIO_PIN_13, GPIO_PIN_RESET);

  /*Configure GPIO pin : PA0 */
  GPIO_InitStruct.Pin = GPIO_PIN_0;
  GPIO_InitStruct.Mode = GPIO_MODE_INPUT;
  GPIO_InitStruct.Pull = GPIO_NOPULL;
  HAL_GPIO_Init(GPIOA, &GPIO_InitStruct);

  /*Configure GPIO pin : PG13 */
  GPIO_InitStruct.Pin = GPIO_PIN_13;
  GPIO_InitStruct.Mode = GPIO_MODE_OUTPUT_PP;
  GPIO_InitStruct.Pull = GPIO_NOPULL;
  GPIO_InitStruct.Speed = GPIO_SPEED_FREQ_LOW;
  HAL_GPIO_Init(GPIOG, &GPIO_InitStruct);

}

/* USER CODE BEGIN 4 */
/**
  * @brief Print the characters to UART (printf).
  * @retval int
  */
#ifdef __GNUC__
  /* With GCC, small printf (option LD Linker->Libraries->Small printf
     set to 'Yes') calls __io_putchar() */
int __io_putchar(int ch)
#else
int fputc(int ch, FILE *f)
#endif /* __GNUC__ */
{
  /* Place your implementation of fputc here */
  /* e.g. write a character to the UART1 and Loop until the end of transmission */
  HAL_UART_Transmit(&huart1, (uint8_t *)&ch, 1, HAL_MAX_DELAY);
  return ch;
}

static void goto_application(void)
{
  printf("Gonna Jump to Application\r\n");
  void (*app_reset_handler)(void) = (void*)(*((volatile uint32_t*) (APP_START_ADDRESS + 4U)));
  // Turn OFF the Green Led to tell the user that Bootloader is not running
  HAL_GPIO_WritePin(GPIOG, GPIO_PIN_13, GPIO_PIN_RESET );    //Green LED OFF
  // Reset the Clock
  HAL_RCC_DeInit();
  HAL_DeInit();
  __set_MSP(*(volatile uint32_t*) APP_START_ADDRESS);
  SysTick->CTRL = 0;
  SysTick->LOAD = 0;
  SysTick->VAL = 0;
  // Jump to application
  app_reset_handler();    //call the app reset handler
}

/* USER CODE END 4 */

void Error_Handler(void)
{
  __disable_irq();
  while (1)
  {
  }
}
